VERSION ""

NS_ :

BS_:

BU_: REF_ECU AUT

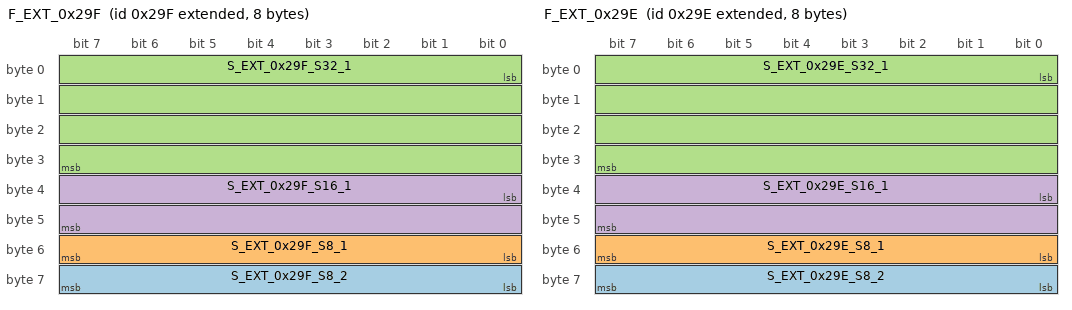
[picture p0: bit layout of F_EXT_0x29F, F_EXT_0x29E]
BO_ 2147484319 F_EXT_0x29F: 8 REF_ECU
 SG_ S_EXT_0x29F_S8_2 : 56|8@1- (1,0) [0|0] "" Vector__XXX
 SG_ S_EXT_0x29F_S8_1 : 48|8@1- (1,0) [0|0] "" Vector__XXX
 SG_ S_EXT_0x29F_S32_1 : 0|32@1- (1,0) [0|0] "" Vector__XXX
 SG_ S_EXT_0x29F_S16_1 : 32|16@1- (1,0) [0|0] "" Vector__XXX

BO_ 2147484318 F_EXT_0x29E: 8 REF_ECU
 SG_ S_EXT_0x29E_S8_2 : 56|8@1- (1,0) [0|0] "" Vector__XXX
 SG_ S_EXT_0x29E_S8_1 : 48|8@1- (1,0) [0|0] "" Vector__XXX
 SG_ S_EXT_0x29E_S32_1 : 0|32@1- (1,0) [0|0] "" Vector__XXX
 SG_ S_EXT_0x29E_S16_1 : 32|16@1- (1,0) [0|0] "" Vector__XXX

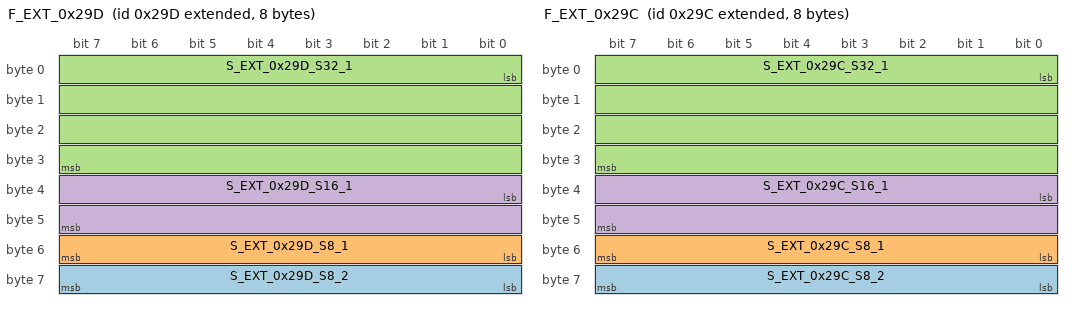
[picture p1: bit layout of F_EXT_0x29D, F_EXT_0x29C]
BO_ 2147484317 F_EXT_0x29D: 8 REF_ECU
 SG_ S_EXT_0x29D_S8_2 : 56|8@1- (1,0) [0|0] "" Vector__XXX
 SG_ S_EXT_0x29D_S8_1 : 48|8@1- (1,0) [0|0] "" Vector__XXX
 SG_ S_EXT_0x29D_S32_1 : 0|32@1- (1,0) [0|0] "" Vector__XXX
 SG_ S_EXT_0x29D_S16_1 : 32|16@1- (1,0) [0|0] "" Vector__XXX

BO_ 2147484316 F_EXT_0x29C: 8 REF_ECU
 SG_ S_EXT_0x29C_S8_2 : 56|8@1- (1,0) [0|0] "" Vector__XXX
 SG_ S_EXT_0x29C_S8_1 : 48|8@1- (1,0) [0|0] "" Vector__XXX
 SG_ S_EXT_0x29C_S32_1 : 0|32@1- (1,0) [0|0] "" Vector__XXX
 SG_ S_EXT_0x29C_S16_1 : 32|16@1- (1,0) [0|0] "" Vector__XXX

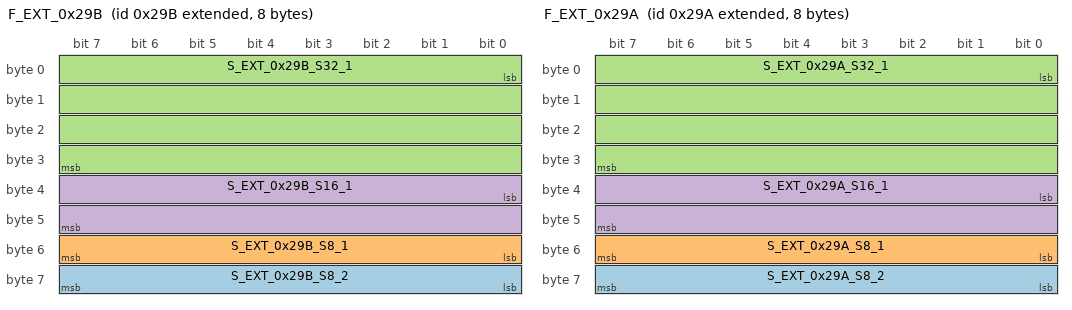
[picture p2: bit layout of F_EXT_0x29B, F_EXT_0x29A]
BO_ 2147484315 F_EXT_0x29B: 8 REF_ECU
 SG_ S_EXT_0x29B_S8_2 : 56|8@1- (1,0) [0|0] "" Vector__XXX
 SG_ S_EXT_0x29B_S8_1 : 48|8@1- (1,0) [0|0] "" Vector__XXX
 SG_ S_EXT_0x29B_S32_1 : 0|32@1- (1,0) [0|0] "" Vector__XXX
 SG_ S_EXT_0x29B_S16_1 : 32|16@1- (1,0) [0|0] "" Vector__XXX

BO_ 2147484314 F_EXT_0x29A: 8 REF_ECU
 SG_ S_EXT_0x29A_S8_2 : 56|8@1- (1,0) [0|0] "" Vector__XXX
 SG_ S_EXT_0x29A_S8_1 : 48|8@1- (1,0) [0|0] "" Vector__XXX
 SG_ S_EXT_0x29A_S32_1 : 0|32@1- (1,0) [0|0] "" Vector__XXX
 SG_ S_EXT_0x29A_S16_1 : 32|16@1- (1,0) [0|0] "" Vector__XXX

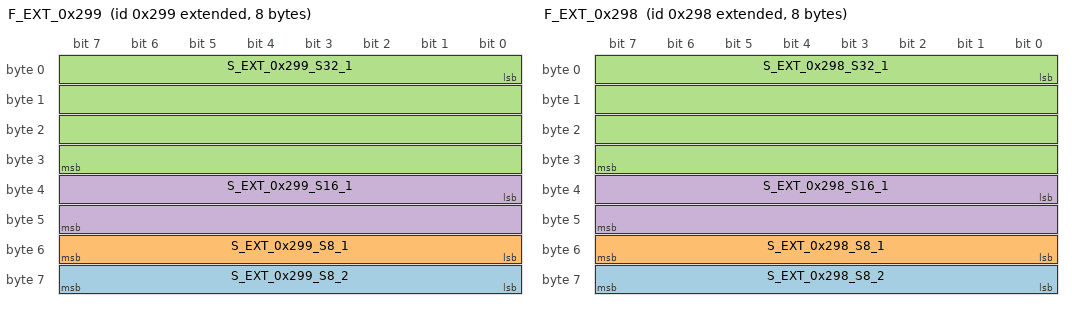
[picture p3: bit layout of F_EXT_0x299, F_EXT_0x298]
BO_ 2147484313 F_EXT_0x299: 8 REF_ECU
 SG_ S_EXT_0x299_S8_2 : 56|8@1- (1,0) [0|0] "" Vector__XXX
 SG_ S_EXT_0x299_S8_1 : 48|8@1- (1,0) [0|0] "" Vector__XXX
 SG_ S_EXT_0x299_S32_1 : 0|32@1- (1,0) [0|0] "" Vector__XXX
 SG_ S_EXT_0x299_S16_1 : 32|16@1- (1,0) [0|0] "" Vector__XXX

BO_ 2147484312 F_EXT_0x298: 8 REF_ECU
 SG_ S_EXT_0x298_S8_2 : 56|8@1- (1,0) [0|0] "" Vector__XXX
 SG_ S_EXT_0x298_S8_1 : 48|8@1- (1,0) [0|0] "" Vector__XXX
 SG_ S_EXT_0x298_S32_1 : 0|32@1- (1,0) [0|0] "" Vector__XXX
 SG_ S_EXT_0x298_S16_1 : 32|16@1- (1,0) [0|0] "" Vector__XXX

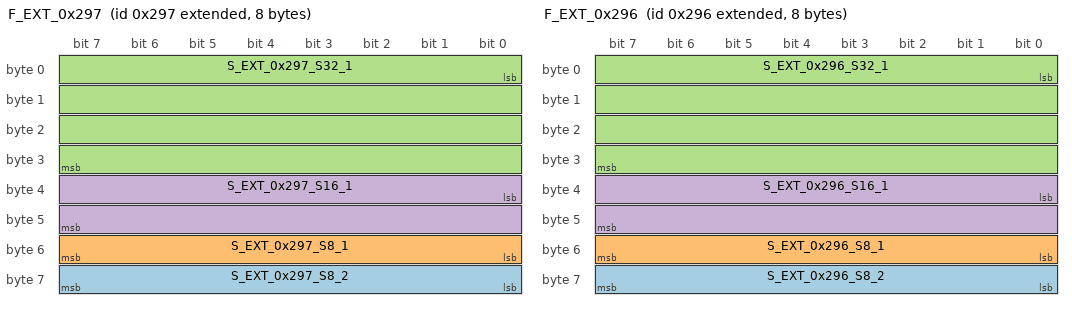
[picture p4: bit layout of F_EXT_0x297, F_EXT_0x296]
BO_ 2147484311 F_EXT_0x297: 8 REF_ECU
 SG_ S_EXT_0x297_S8_2 : 56|8@1- (1,0) [0|0] "" Vector__XXX
 SG_ S_EXT_0x297_S8_1 : 48|8@1- (1,0) [0|0] "" Vector__XXX
 SG_ S_EXT_0x297_S32_1 : 0|32@1- (1,0) [0|0] "" Vector__XXX
 SG_ S_EXT_0x297_S16_1 : 32|16@1- (1,0) [0|0] "" Vector__XXX

BO_ 2147484310 F_EXT_0x296: 8 REF_ECU
 SG_ S_EXT_0x296_S8_2 : 56|8@1- (1,0) [0|0] "" Vector__XXX
 SG_ S_EXT_0x296_S8_1 : 48|8@1- (1,0) [0|0] "" Vector__XXX
 SG_ S_EXT_0x296_S32_1 : 0|32@1- (1,0) [0|0] "" Vector__XXX
 SG_ S_EXT_0x296_S16_1 : 32|16@1- (1,0) [0|0] "" Vector__XXX

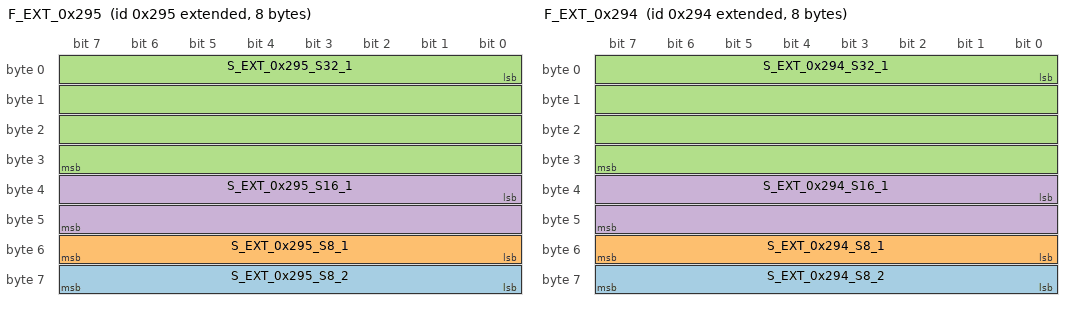
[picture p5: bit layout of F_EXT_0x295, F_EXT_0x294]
BO_ 2147484309 F_EXT_0x295: 8 REF_ECU
 SG_ S_EXT_0x295_S8_2 : 56|8@1- (1,0) [0|0] "" Vector__XXX
 SG_ S_EXT_0x295_S8_1 : 48|8@1- (1,0) [0|0] "" Vector__XXX
 SG_ S_EXT_0x295_S32_1 : 0|32@1- (1,0) [0|0] "" Vector__XXX
 SG_ S_EXT_0x295_S16_1 : 32|16@1- (1,0) [0|0] "" Vector__XXX

BO_ 2147484308 F_EXT_0x294: 8 REF_ECU
 SG_ S_EXT_0x294_S8_2 : 56|8@1- (1,0) [0|0] "" Vector__XXX
 SG_ S_EXT_0x294_S8_1 : 48|8@1- (1,0) [0|0] "" Vector__XXX
 SG_ S_EXT_0x294_S32_1 : 0|32@1- (1,0) [0|0] "" Vector__XXX
 SG_ S_EXT_0x294_S16_1 : 32|16@1- (1,0) [0|0] "" Vector__XXX

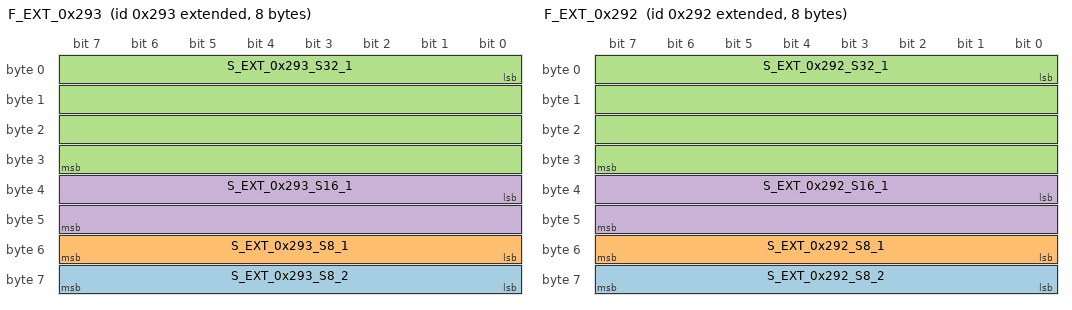
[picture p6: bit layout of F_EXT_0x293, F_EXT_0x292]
BO_ 2147484307 F_EXT_0x293: 8 REF_ECU
 SG_ S_EXT_0x293_S8_2 : 56|8@1- (1,0) [0|0] "" Vector__XXX
 SG_ S_EXT_0x293_S8_1 : 48|8@1- (1,0) [0|0] "" Vector__XXX
 SG_ S_EXT_0x293_S32_1 : 0|32@1- (1,0) [0|0] "" Vector__XXX
 SG_ S_EXT_0x293_S16_1 : 32|16@1- (1,0) [0|0] "" Vector__XXX

BO_ 2147484306 F_EXT_0x292: 8 REF_ECU
 SG_ S_EXT_0x292_S8_2 : 56|8@1- (1,0) [0|0] "" Vector__XXX
 SG_ S_EXT_0x292_S8_1 : 48|8@1- (1,0) [0|0] "" Vector__XXX
 SG_ S_EXT_0x292_S32_1 : 0|32@1- (1,0) [0|0] "" Vector__XXX
 SG_ S_EXT_0x292_S16_1 : 32|16@1- (1,0) [0|0] "" Vector__XXX

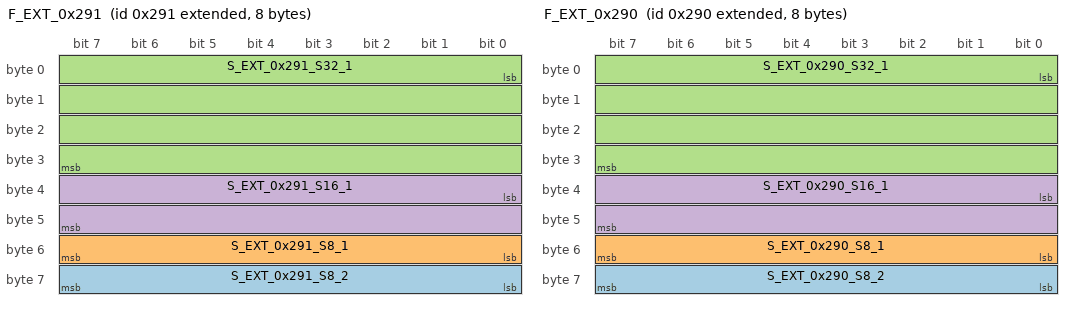
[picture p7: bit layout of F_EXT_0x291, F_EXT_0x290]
BO_ 2147484305 F_EXT_0x291: 8 REF_ECU
 SG_ S_EXT_0x291_S8_2 : 56|8@1- (1,0) [0|0] "" Vector__XXX
 SG_ S_EXT_0x291_S8_1 : 48|8@1- (1,0) [0|0] "" Vector__XXX
 SG_ S_EXT_0x291_S32_1 : 0|32@1- (1,0) [0|0] "" Vector__XXX
 SG_ S_EXT_0x291_S16_1 : 32|16@1- (1,0) [0|0] "" Vector__XXX

BO_ 2147484304 F_EXT_0x290: 8 REF_ECU
 SG_ S_EXT_0x290_S8_2 : 56|8@1- (1,0) [0|0] "" Vector__XXX
 SG_ S_EXT_0x290_S8_1 : 48|8@1- (1,0) [0|0] "" Vector__XXX
 SG_ S_EXT_0x290_S32_1 : 0|32@1- (1,0) [0|0] "" Vector__XXX
 SG_ S_EXT_0x290_S16_1 : 32|16@1- (1,0) [0|0] "" Vector__XXX

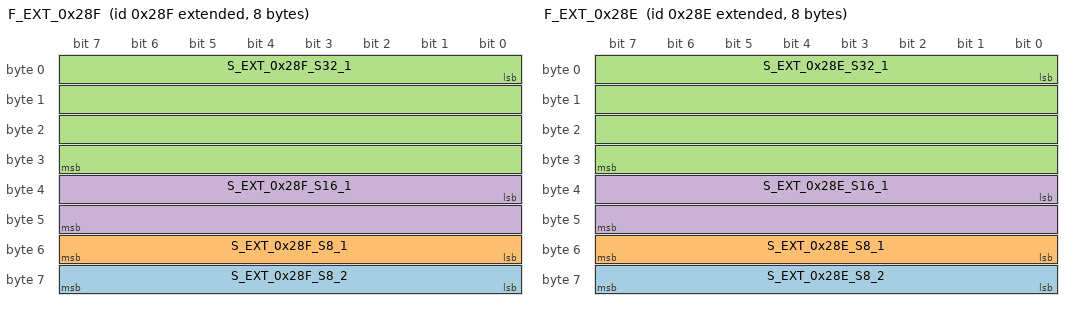
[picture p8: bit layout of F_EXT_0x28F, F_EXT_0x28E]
BO_ 2147484303 F_EXT_0x28F: 8 REF_ECU
 SG_ S_EXT_0x28F_S8_2 : 56|8@1- (1,0) [0|0] "" Vector__XXX
 SG_ S_EXT_0x28F_S8_1 : 48|8@1- (1,0) [0|0] "" Vector__XXX
 SG_ S_EXT_0x28F_S32_1 : 0|32@1- (1,0) [0|0] "" Vector__XXX
 SG_ S_EXT_0x28F_S16_1 : 32|16@1- (1,0) [0|0] "" Vector__XXX

BO_ 2147484302 F_EXT_0x28E: 8 REF_ECU
 SG_ S_EXT_0x28E_S8_2 : 56|8@1- (1,0) [0|0] "" Vector__XXX
 SG_ S_EXT_0x28E_S8_1 : 48|8@1- (1,0) [0|0] "" Vector__XXX
 SG_ S_EXT_0x28E_S32_1 : 0|32@1- (1,0) [0|0] "" Vector__XXX
 SG_ S_EXT_0x28E_S16_1 : 32|16@1- (1,0) [0|0] "" Vector__XXX

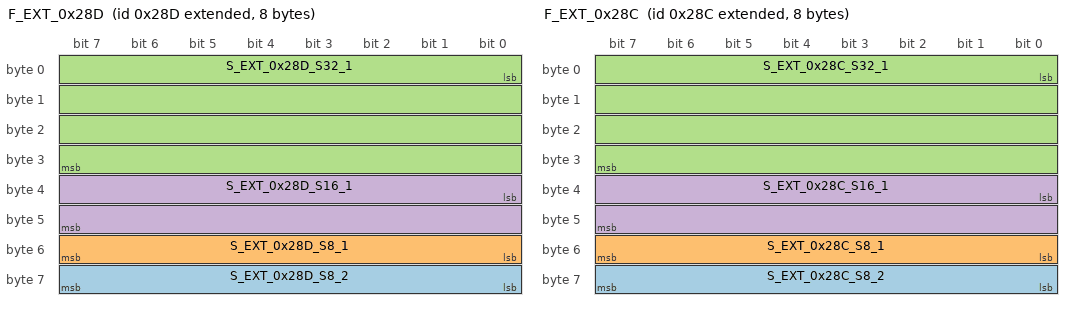
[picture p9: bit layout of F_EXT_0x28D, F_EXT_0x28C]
BO_ 2147484301 F_EXT_0x28D: 8 REF_ECU
 SG_ S_EXT_0x28D_S8_2 : 56|8@1- (1,0) [0|0] "" Vector__XXX
 SG_ S_EXT_0x28D_S8_1 : 48|8@1- (1,0) [0|0] "" Vector__XXX
 SG_ S_EXT_0x28D_S32_1 : 0|32@1- (1,0) [0|0] "" Vector__XXX
 SG_ S_EXT_0x28D_S16_1 : 32|16@1- (1,0) [0|0] "" Vector__XXX

BO_ 2147484300 F_EXT_0x28C: 8 REF_ECU
 SG_ S_EXT_0x28C_S8_2 : 56|8@1- (1,0) [0|0] "" Vector__XXX
 SG_ S_EXT_0x28C_S8_1 : 48|8@1- (1,0) [0|0] "" Vector__XXX
 SG_ S_EXT_0x28C_S32_1 : 0|32@1- (1,0) [0|0] "" Vector__XXX
 SG_ S_EXT_0x28C_S16_1 : 32|16@1- (1,0) [0|0] "" Vector__XXX

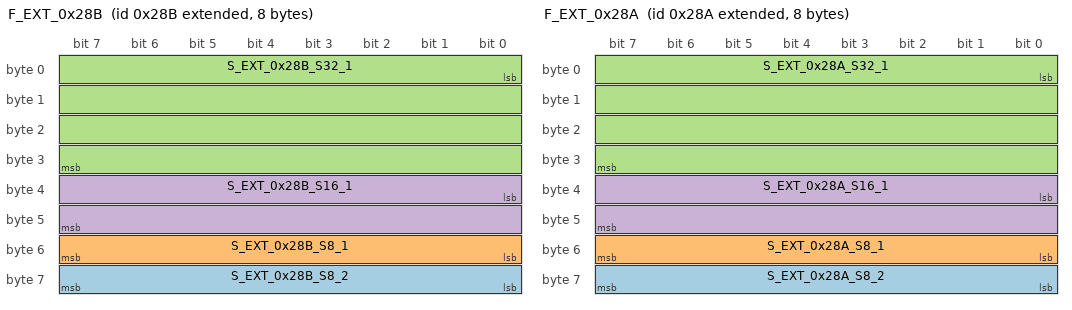
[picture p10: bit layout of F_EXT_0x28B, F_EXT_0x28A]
BO_ 2147484299 F_EXT_0x28B: 8 REF_ECU
 SG_ S_EXT_0x28B_S8_2 : 56|8@1- (1,0) [0|0] "" Vector__XXX
 SG_ S_EXT_0x28B_S8_1 : 48|8@1- (1,0) [0|0] "" Vector__XXX
 SG_ S_EXT_0x28B_S32_1 : 0|32@1- (1,0) [0|0] "" Vector__XXX
 SG_ S_EXT_0x28B_S16_1 : 32|16@1- (1,0) [0|0] "" Vector__XXX

BO_ 2147484298 F_EXT_0x28A: 8 REF_ECU
 SG_ S_EXT_0x28A_S8_2 : 56|8@1- (1,0) [0|0] "" Vector__XXX
 SG_ S_EXT_0x28A_S8_1 : 48|8@1- (1,0) [0|0] "" Vector__XXX
 SG_ S_EXT_0x28A_S32_1 : 0|32@1- (1,0) [0|0] "" Vector__XXX
 SG_ S_EXT_0x28A_S16_1 : 32|16@1- (1,0) [0|0] "" Vector__XXX

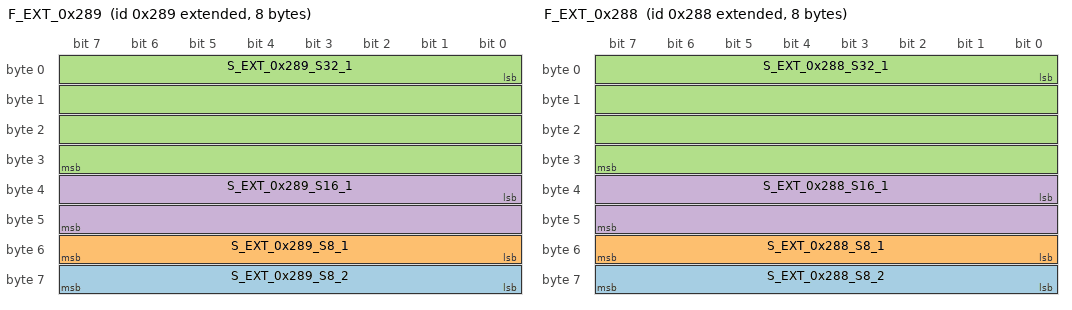
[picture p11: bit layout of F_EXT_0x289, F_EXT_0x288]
BO_ 2147484297 F_EXT_0x289: 8 REF_ECU
 SG_ S_EXT_0x289_S8_2 : 56|8@1- (1,0) [0|0] "" Vector__XXX
 SG_ S_EXT_0x289_S8_1 : 48|8@1- (1,0) [0|0] "" Vector__XXX
 SG_ S_EXT_0x289_S32_1 : 0|32@1- (1,0) [0|0] "" Vector__XXX
 SG_ S_EXT_0x289_S16_1 : 32|16@1- (1,0) [0|0] "" Vector__XXX

BO_ 2147484296 F_EXT_0x288: 8 REF_ECU
 SG_ S_EXT_0x288_S8_2 : 56|8@1- (1,0) [0|0] "" Vector__XXX
 SG_ S_EXT_0x288_S8_1 : 48|8@1- (1,0) [0|0] "" Vector__XXX
 SG_ S_EXT_0x288_S32_1 : 0|32@1- (1,0) [0|0] "" Vector__XXX
 SG_ S_EXT_0x288_S16_1 : 32|16@1- (1,0) [0|0] "" Vector__XXX

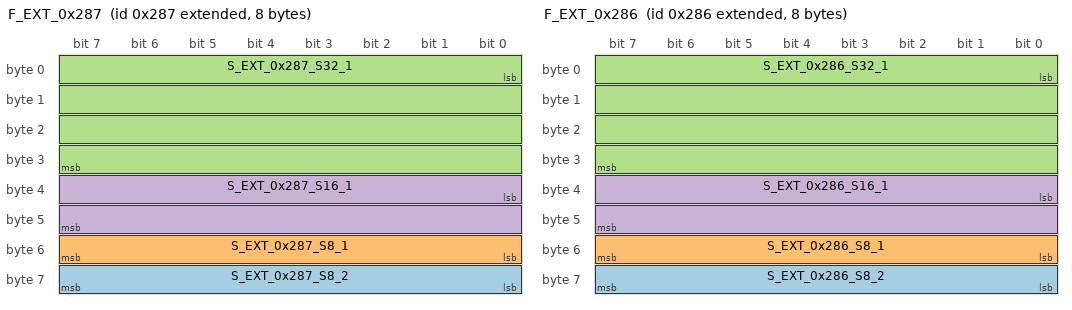
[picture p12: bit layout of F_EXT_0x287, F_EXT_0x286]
BO_ 2147484295 F_EXT_0x287: 8 REF_ECU
 SG_ S_EXT_0x287_S8_2 : 56|8@1- (1,0) [0|0] "" Vector__XXX
 SG_ S_EXT_0x287_S8_1 : 48|8@1- (1,0) [0|0] "" Vector__XXX
 SG_ S_EXT_0x287_S32_1 : 0|32@1- (1,0) [0|0] "" Vector__XXX
 SG_ S_EXT_0x287_S16_1 : 32|16@1- (1,0) [0|0] "" Vector__XXX

BO_ 2147484294 F_EXT_0x286: 8 REF_ECU
 SG_ S_EXT_0x286_S8_2 : 56|8@1- (1,0) [0|0] "" Vector__XXX
 SG_ S_EXT_0x286_S8_1 : 48|8@1- (1,0) [0|0] "" Vector__XXX
 SG_ S_EXT_0x286_S32_1 : 0|32@1- (1,0) [0|0] "" Vector__XXX
 SG_ S_EXT_0x286_S16_1 : 32|16@1- (1,0) [0|0] "" Vector__XXX

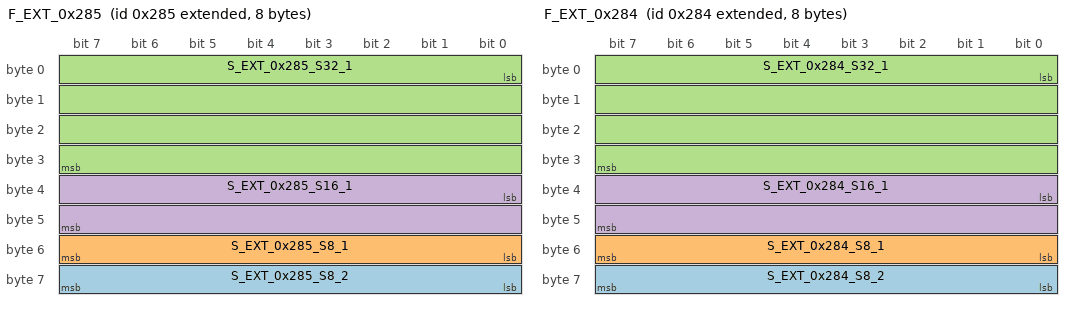
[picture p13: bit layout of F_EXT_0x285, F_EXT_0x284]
BO_ 2147484293 F_EXT_0x285: 8 REF_ECU
 SG_ S_EXT_0x285_S8_2 : 56|8@1- (1,0) [0|0] "" Vector__XXX
 SG_ S_EXT_0x285_S8_1 : 48|8@1- (1,0) [0|0] "" Vector__XXX
 SG_ S_EXT_0x285_S32_1 : 0|32@1- (1,0) [0|0] "" Vector__XXX
 SG_ S_EXT_0x285_S16_1 : 32|16@1- (1,0) [0|0] "" Vector__XXX

BO_ 2147484292 F_EXT_0x284: 8 REF_ECU
 SG_ S_EXT_0x284_S8_2 : 56|8@1- (1,0) [0|0] "" Vector__XXX
 SG_ S_EXT_0x284_S8_1 : 48|8@1- (1,0) [0|0] "" Vector__XXX
 SG_ S_EXT_0x284_S32_1 : 0|32@1- (1,0) [0|0] "" Vector__XXX
 SG_ S_EXT_0x284_S16_1 : 32|16@1- (1,0) [0|0] "" Vector__XXX

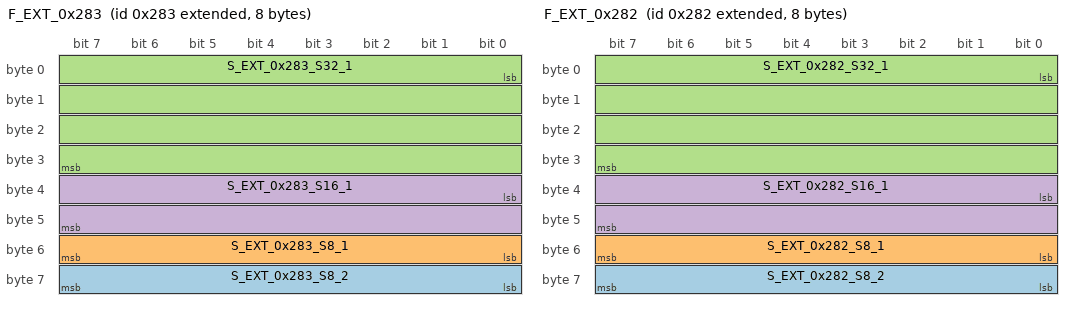
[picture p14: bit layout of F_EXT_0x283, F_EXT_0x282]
BO_ 2147484291 F_EXT_0x283: 8 REF_ECU
 SG_ S_EXT_0x283_S8_2 : 56|8@1- (1,0) [0|0] "" Vector__XXX
 SG_ S_EXT_0x283_S8_1 : 48|8@1- (1,0) [0|0] "" Vector__XXX
 SG_ S_EXT_0x283_S32_1 : 0|32@1- (1,0) [0|0] "" Vector__XXX
 SG_ S_EXT_0x283_S16_1 : 32|16@1- (1,0) [0|0] "" Vector__XXX

BO_ 2147484290 F_EXT_0x282: 8 REF_ECU
 SG_ S_EXT_0x282_S8_2 : 56|8@1- (1,0) [0|0] "" Vector__XXX
 SG_ S_EXT_0x282_S8_1 : 48|8@1- (1,0) [0|0] "" Vector__XXX
 SG_ S_EXT_0x282_S32_1 : 0|32@1- (1,0) [0|0] "" Vector__XXX
 SG_ S_EXT_0x282_S16_1 : 32|16@1- (1,0) [0|0] "" Vector__XXX

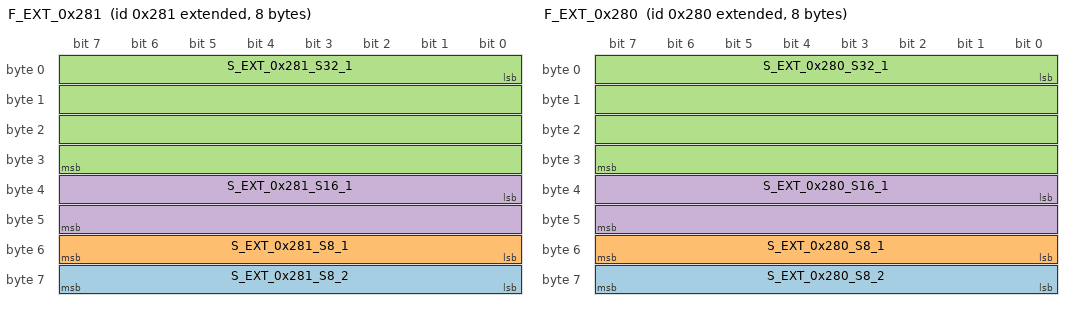
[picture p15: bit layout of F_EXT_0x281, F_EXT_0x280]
BO_ 2147484289 F_EXT_0x281: 8 REF_ECU
 SG_ S_EXT_0x281_S8_2 : 56|8@1- (1,0) [0|0] "" Vector__XXX
 SG_ S_EXT_0x281_S8_1 : 48|8@1- (1,0) [0|0] "" Vector__XXX
 SG_ S_EXT_0x281_S32_1 : 0|32@1- (1,0) [0|0] "" Vector__XXX
 SG_ S_EXT_0x281_S16_1 : 32|16@1- (1,0) [0|0] "" Vector__XXX

BO_ 2147484288 F_EXT_0x280: 8 REF_ECU
 SG_ S_EXT_0x280_S8_2 : 56|8@1- (1,0) [0|0] "" Vector__XXX
 SG_ S_EXT_0x280_S8_1 : 48|8@1- (1,0) [0|0] "" Vector__XXX
 SG_ S_EXT_0x280_S32_1 : 0|32@1- (1,0) [0|0] "" Vector__XXX
 SG_ S_EXT_0x280_S16_1 : 32|16@1- (1,0) [0|0] "" Vector__XXX

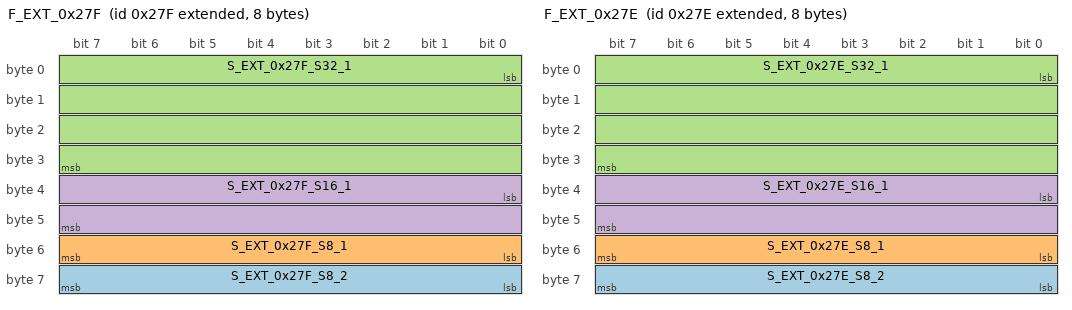
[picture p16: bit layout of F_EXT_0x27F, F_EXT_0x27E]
BO_ 2147484287 F_EXT_0x27F: 8 REF_ECU
 SG_ S_EXT_0x27F_S8_2 : 56|8@1- (1,0) [0|0] "" Vector__XXX
 SG_ S_EXT_0x27F_S8_1 : 48|8@1- (1,0) [0|0] "" Vector__XXX
 SG_ S_EXT_0x27F_S32_1 : 0|32@1- (1,0) [0|0] "" Vector__XXX
 SG_ S_EXT_0x27F_S16_1 : 32|16@1- (1,0) [0|0] "" Vector__XXX

BO_ 2147484286 F_EXT_0x27E: 8 REF_ECU
 SG_ S_EXT_0x27E_S8_2 : 56|8@1- (1,0) [0|0] "" Vector__XXX
 SG_ S_EXT_0x27E_S8_1 : 48|8@1- (1,0) [0|0] "" Vector__XXX
 SG_ S_EXT_0x27E_S32_1 : 0|32@1- (1,0) [0|0] "" Vector__XXX
 SG_ S_EXT_0x27E_S16_1 : 32|16@1- (1,0) [0|0] "" Vector__XXX

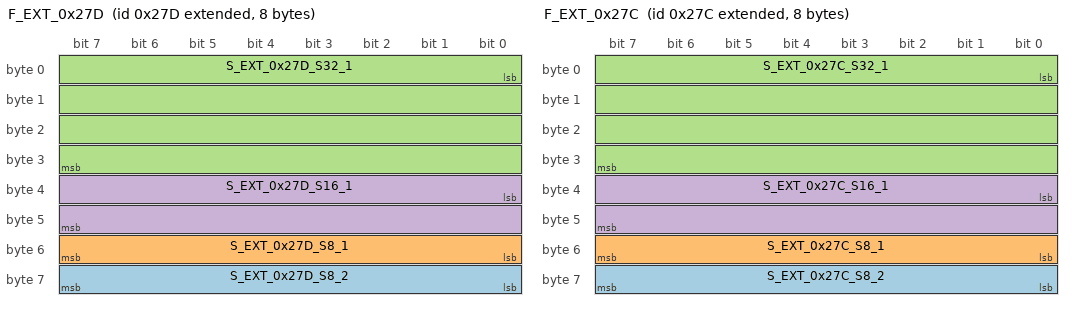
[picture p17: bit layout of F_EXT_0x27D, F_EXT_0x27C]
BO_ 2147484285 F_EXT_0x27D: 8 REF_ECU
 SG_ S_EXT_0x27D_S8_2 : 56|8@1- (1,0) [0|0] "" Vector__XXX
 SG_ S_EXT_0x27D_S8_1 : 48|8@1- (1,0) [0|0] "" Vector__XXX
 SG_ S_EXT_0x27D_S32_1 : 0|32@1- (1,0) [0|0] "" Vector__XXX
 SG_ S_EXT_0x27D_S16_1 : 32|16@1- (1,0) [0|0] "" Vector__XXX

BO_ 2147484284 F_EXT_0x27C: 8 REF_ECU
 SG_ S_EXT_0x27C_S8_2 : 56|8@1- (1,0) [0|0] "" Vector__XXX
 SG_ S_EXT_0x27C_S8_1 : 48|8@1- (1,0) [0|0] "" Vector__XXX
 SG_ S_EXT_0x27C_S32_1 : 0|32@1- (1,0) [0|0] "" Vector__XXX
 SG_ S_EXT_0x27C_S16_1 : 32|16@1- (1,0) [0|0] "" Vector__XXX

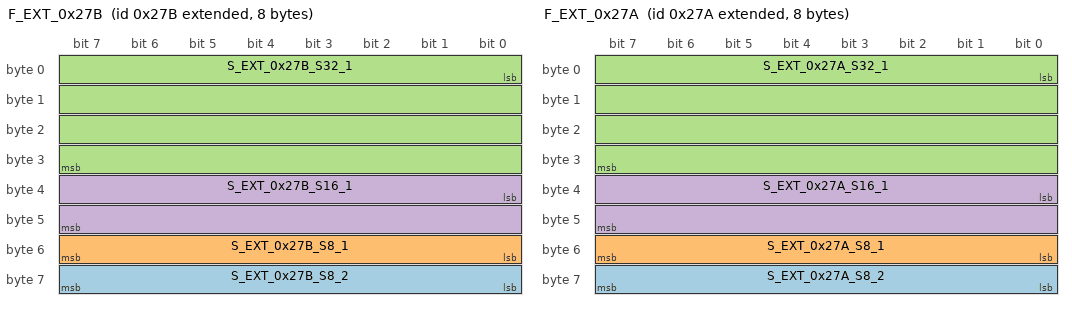
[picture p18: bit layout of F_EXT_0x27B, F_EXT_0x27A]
BO_ 2147484283 F_EXT_0x27B: 8 REF_ECU
 SG_ S_EXT_0x27B_S8_2 : 56|8@1- (1,0) [0|0] "" Vector__XXX
 SG_ S_EXT_0x27B_S8_1 : 48|8@1- (1,0) [0|0] "" Vector__XXX
 SG_ S_EXT_0x27B_S32_1 : 0|32@1- (1,0) [0|0] "" Vector__XXX
 SG_ S_EXT_0x27B_S16_1 : 32|16@1- (1,0) [0|0] "" Vector__XXX

BO_ 2147484282 F_EXT_0x27A: 8 REF_ECU
 SG_ S_EXT_0x27A_S8_2 : 56|8@1- (1,0) [0|0] "" Vector__XXX
 SG_ S_EXT_0x27A_S8_1 : 48|8@1- (1,0) [0|0] "" Vector__XXX
 SG_ S_EXT_0x27A_S32_1 : 0|32@1- (1,0) [0|0] "" Vector__XXX
 SG_ S_EXT_0x27A_S16_1 : 32|16@1- (1,0) [0|0] "" Vector__XXX

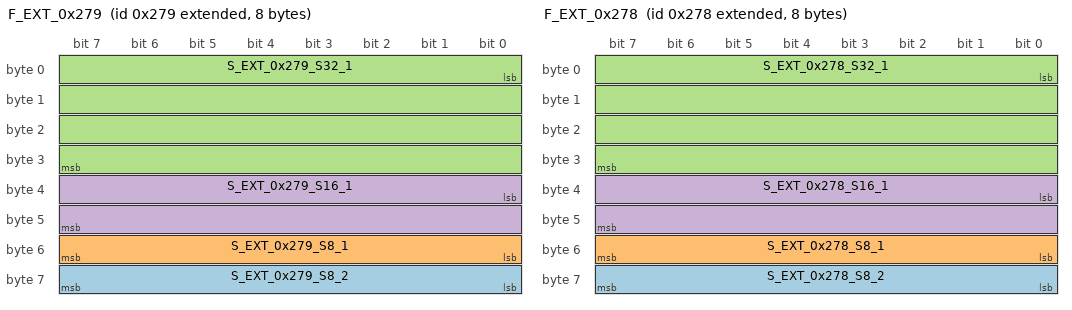
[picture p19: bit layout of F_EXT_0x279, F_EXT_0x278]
BO_ 2147484281 F_EXT_0x279: 8 REF_ECU
 SG_ S_EXT_0x279_S8_2 : 56|8@1- (1,0) [0|0] "" Vector__XXX
 SG_ S_EXT_0x279_S8_1 : 48|8@1- (1,0) [0|0] "" Vector__XXX
 SG_ S_EXT_0x279_S32_1 : 0|32@1- (1,0) [0|0] "" Vector__XXX
 SG_ S_EXT_0x279_S16_1 : 32|16@1- (1,0) [0|0] "" Vector__XXX

BO_ 2147484280 F_EXT_0x278: 8 REF_ECU
 SG_ S_EXT_0x278_S8_2 : 56|8@1- (1,0) [0|0] "" Vector__XXX
 SG_ S_EXT_0x278_S8_1 : 48|8@1- (1,0) [0|0] "" Vector__XXX
 SG_ S_EXT_0x278_S32_1 : 0|32@1- (1,0) [0|0] "" Vector__XXX
 SG_ S_EXT_0x278_S16_1 : 32|16@1- (1,0) [0|0] "" Vector__XXX

BO_ 2147484279 F_EXT_0x277: 8 REF_ECU
 SG_ S_EXT_0x277_S8_2 : 56|8@1- (1,0) [0|0] "" Vector__XXX
 SG_ S_EXT_0x277_S8_1 : 48|8@1- (1,0) [0|0] "" Vector__XXX
 SG_ S_EXT_0x277_S32_1 : 0|32@1- (1,0) [0|0] "" Vector__XXX
 SG_ S_EXT_0x277_S16_1 : 32|16@1- (1,0) [0|0] "" Vector__XXX

BO_ 2147484278 F_EXT_0x276: 8 REF_ECU
 SG_ S_EXT_0x276_S8_2 : 56|8@1- (1,0) [0|0] "" Vector__XXX
 SG_ S_EXT_0x276_S8_1 : 48|8@1- (1,0) [0|0] "" Vector__XXX
 SG_ S_EXT_0x276_S32_1 : 0|32@1- (1,0) [0|0] "" Vector__XXX
 SG_ S_EXT_0x276_S16_1 : 32|16@1- (1,0) [0|0] "" Vector__XXX

BO_ 2147484277 F_EXT_0x275: 8 REF_ECU
 SG_ S_EXT_0x275_S8_2 : 56|8@1- (1,0) [0|0] "" Vector__XXX
 SG_ S_EXT_0x275_S8_1 : 48|8@1- (1,0) [0|0] "" Vector__XXX
 SG_ S_EXT_0x275_S32_1 : 0|32@1- (1,0) [0|0] "" Vector__XXX
 SG_ S_EXT_0x275_S16_1 : 32|16@1- (1,0) [0|0] "" Vector__XXX

BO_ 2147484276 F_EXT_0x274: 8 REF_ECU
 SG_ S_EXT_0x274_S8_2 : 56|8@1- (1,0) [0|0] "" Vector__XXX
 SG_ S_EXT_0x274_S8_1 : 48|8@1- (1,0) [0|0] "" Vector__XXX
 SG_ S_EXT_0x274_S32_1 : 0|32@1- (1,0) [0|0] "" Vector__XXX
 SG_ S_EXT_0x274_S16_1 : 32|16@1- (1,0) [0|0] "" Vector__XXX

BO_ 2147484275 F_EXT_0x273: 8 REF_ECU
 SG_ S_EXT_0x273_S8_2 : 56|8@1- (1,0) [0|0] "" Vector__XXX
 SG_ S_EXT_0x273_S8_1 : 48|8@1- (1,0) [0|0] "" Vector__XXX
 SG_ S_EXT_0x273_S32_1 : 0|32@1- (1,0) [0|0] "" Vector__XXX
 SG_ S_EXT_0x273_S16_1 : 32|16@1- (1,0) [0|0] "" Vector__XXX

BO_ 2147484274 F_EXT_0x272: 8 REF_ECU
 SG_ S_EXT_0x272_S8_2 : 56|8@1- (1,0) [0|0] "" Vector__XXX
 SG_ S_EXT_0x272_S8_1 : 48|8@1- (1,0) [0|0] "" Vector__XXX
 SG_ S_EXT_0x272_S32_1 : 0|32@1- (1,0) [0|0] "" Vector__XXX
 SG_ S_EXT_0x272_S16_1 : 32|16@1- (1,0) [0|0] "" Vector__XXX

BO_ 2147484273 F_EXT_0x271: 8 REF_ECU
 SG_ S_EXT_0x271_S8_2 : 56|8@1- (1,0) [0|0] "" Vector__XXX
 SG_ S_EXT_0x271_S8_1 : 48|8@1- (1,0) [0|0] "" Vector__XXX
 SG_ S_EXT_0x271_S32_1 : 0|32@1- (1,0) [0|0] "" Vector__XXX
 SG_ S_EXT_0x271_S16_1 : 32|16@1- (1,0) [0|0] "" Vector__XXX

BO_ 2147484272 F_EXT_0x270: 8 REF_ECU
 SG_ S_EXT_0x270_S8_2 : 56|8@1- (1,0) [0|0] "" Vector__XXX
 SG_ S_EXT_0x270_S8_1 : 48|8@1- (1,0) [0|0] "" Vector__XXX
 SG_ S_EXT_0x270_S32_1 : 0|32@1- (1,0) [0|0] "" Vector__XXX
 SG_ S_EXT_0x270_S16_1 : 32|16@1- (1,0) [0|0] "" Vector__XXX

BO_ 2147484271 F_EXT_0x26F: 8 REF_ECU
 SG_ S_EXT_0x26F_S8_2 : 56|8@1- (1,0) [0|0] "" Vector__XXX
 SG_ S_EXT_0x26F_S8_1 : 48|8@1- (1,0) [0|0] "" Vector__XXX
 SG_ S_EXT_0x26F_S32_1 : 0|32@1- (1,0) [0|0] "" Vector__XXX
 SG_ S_EXT_0x26F_S16_1 : 32|16@1- (1,0) [0|0] "" Vector__XXX

BO_ 2147484270 F_EXT_0x26E: 8 REF_ECU
 SG_ S_EXT_0x26E_S8_2 : 56|8@1- (1,0) [0|0] "" Vector__XXX
 SG_ S_EXT_0x26E_S8_1 : 48|8@1- (1,0) [0|0] "" Vector__XXX
 SG_ S_EXT_0x26E_S32_1 : 0|32@1- (1,0) [0|0] "" Vector__XXX
 SG_ S_EXT_0x26E_S16_1 : 32|16@1- (1,0) [0|0] "" Vector__XXX

BO_ 2147484269 F_EXT_0x26D: 8 REF_ECU
 SG_ S_EXT_0x26D_S8_2 : 56|8@1- (1,0) [0|0] "" Vector__XXX
 SG_ S_EXT_0x26D_S8_1 : 48|8@1- (1,0) [0|0] "" Vector__XXX
 SG_ S_EXT_0x26D_S32_1 : 0|32@1- (1,0) [0|0] "" Vector__XXX
 SG_ S_EXT_0x26D_S16_1 : 32|16@1- (1,0) [0|0] "" Vector__XXX

BO_ 2147484268 F_EXT_0x26C: 8 REF_ECU
 SG_ S_EXT_0x26C_S8_2 : 56|8@1- (1,0) [0|0] "" Vector__XXX
 SG_ S_EXT_0x26C_S8_1 : 48|8@1- (1,0) [0|0] "" Vector__XXX
 SG_ S_EXT_0x26C_S32_1 : 0|32@1- (1,0) [0|0] "" Vector__XXX
 SG_ S_EXT_0x26C_S16_1 : 32|16@1- (1,0) [0|0] "" Vector__XXX

BO_ 2147484267 F_EXT_0x26B: 8 REF_ECU
 SG_ S_EXT_0x26B_S8_2 : 56|8@1- (1,0) [0|0] "" Vector__XXX
 SG_ S_EXT_0x26B_S8_1 : 48|8@1- (1,0) [0|0] "" Vector__XXX
 SG_ S_EXT_0x26B_S32_1 : 0|32@1- (1,0) [0|0] "" Vector__XXX
 SG_ S_EXT_0x26B_S16_1 : 32|16@1- (1,0) [0|0] "" Vector__XXX

BO_ 2147484266 F_EXT_0x26A: 8 REF_ECU
 SG_ S_EXT_0x26A_S8_2 : 56|8@1- (1,0) [0|0] "" Vector__XXX
 SG_ S_EXT_0x26A_S8_1 : 48|8@1- (1,0) [0|0] "" Vector__XXX
 SG_ S_EXT_0x26A_S32_1 : 0|32@1- (1,0) [0|0] "" Vector__XXX
 SG_ S_EXT_0x26A_S16_1 : 32|16@1- (1,0) [0|0] "" Vector__XXX

BO_ 2147484265 F_EXT_0x269: 8 REF_ECU
 SG_ S_EXT_0x269_S8_2 : 56|8@1- (1,0) [0|0] "" Vector__XXX
 SG_ S_EXT_0x269_S8_1 : 48|8@1- (1,0) [0|0] "" Vector__XXX
 SG_ S_EXT_0x269_S32_1 : 0|32@1- (1,0) [0|0] "" Vector__XXX
 SG_ S_EXT_0x269_S16_1 : 32|16@1- (1,0) [0|0] "" Vector__XXX

BO_ 2147484264 F_EXT_0x268: 8 REF_ECU
 SG_ S_EXT_0x268_S8_2 : 56|8@1- (1,0) [0|0] "" Vector__XXX
 SG_ S_EXT_0x268_S8_1 : 48|8@1- (1,0) [0|0] "" Vector__XXX
 SG_ S_EXT_0x268_S32_1 : 0|32@1- (1,0) [0|0] "" Vector__XXX
 SG_ S_EXT_0x268_S16_1 : 32|16@1- (1,0) [0|0] "" Vector__XXX

BO_ 2147484263 F_EXT_0x267: 8 REF_ECU
 SG_ S_EXT_0x267_S8_2 : 56|8@1- (1,0) [0|0] "" Vector__XXX
 SG_ S_EXT_0x267_S8_1 : 48|8@1- (1,0) [0|0] "" Vector__XXX
 SG_ S_EXT_0x267_S32_1 : 0|32@1- (1,0) [0|0] "" Vector__XXX
 SG_ S_EXT_0x267_S16_1 : 32|16@1- (1,0) [0|0] "" Vector__XXX

BO_ 2147484262 F_EXT_0x266: 8 REF_ECU
 SG_ S_EXT_0x266_S8_2 : 56|8@1- (1,0) [0|0] "" Vector__XXX
 SG_ S_EXT_0x266_S8_1 : 48|8@1- (1,0) [0|0] "" Vector__XXX
 SG_ S_EXT_0x266_S32_1 : 0|32@1- (1,0) [0|0] "" Vector__XXX
 SG_ S_EXT_0x266_S16_1 : 32|16@1- (1,0) [0|0] "" Vector__XXX

BO_ 2147484261 F_EXT_0x265: 8 REF_ECU
 SG_ S_EXT_0x265_S8_2 : 56|8@1- (1,0) [0|0] "" Vector__XXX
 SG_ S_EXT_0x265_S8_1 : 48|8@1- (1,0) [0|0] "" Vector__XXX
 SG_ S_EXT_0x265_S32_1 : 0|32@1- (1,0) [0|0] "" Vector__XXX
 SG_ S_EXT_0x265_S16_1 : 32|16@1- (1,0) [0|0] "" Vector__XXX

BO_ 2147484260 F_EXT_0x264: 8 REF_ECU
 SG_ S_EXT_0x264_S8_2 : 56|8@1- (1,0) [0|0] "" Vector__XXX
 SG_ S_EXT_0x264_S8_1 : 48|8@1- (1,0) [0|0] "" Vector__XXX
 SG_ S_EXT_0x264_S32_1 : 0|32@1- (1,0) [0|0] "" Vector__XXX
 SG_ S_EXT_0x264_S16_1 : 32|16@1- (1,0) [0|0] "" Vector__XXX

BO_ 2147484259 F_EXT_0x263: 8 REF_ECU
 SG_ S_EXT_0x263_S8_2 : 56|8@1- (1,0) [0|0] "" Vector__XXX
 SG_ S_EXT_0x263_S8_1 : 48|8@1- (1,0) [0|0] "" Vector__XXX
 SG_ S_EXT_0x263_S32_1 : 0|32@1- (1,0) [0|0] "" Vector__XXX
 SG_ S_EXT_0x263_S16_1 : 32|16@1- (1,0) [0|0] "" Vector__XXX

BO_ 2147484258 F_EXT_0x262: 8 REF_ECU
 SG_ S_EXT_0x262_S8_2 : 56|8@1- (1,0) [0|0] "" Vector__XXX
 SG_ S_EXT_0x262_S8_1 : 48|8@1- (1,0) [0|0] "" Vector__XXX
 SG_ S_EXT_0x262_S32_1 : 0|32@1- (1,0) [0|0] "" Vector__XXX
 SG_ S_EXT_0x262_S16_1 : 32|16@1- (1,0) [0|0] "" Vector__XXX

BO_ 2147484257 F_EXT_0x261: 8 REF_ECU
 SG_ S_EXT_0x261_S8_2 : 56|8@1- (1,0) [0|0] "" Vector__XXX
 SG_ S_EXT_0x261_S8_1 : 48|8@1- (1,0) [0|0] "" Vector__XXX
 SG_ S_EXT_0x261_S32_1 : 0|32@1- (1,0) [0|0] "" Vector__XXX
 SG_ S_EXT_0x261_S16_1 : 32|16@1- (1,0) [0|0] "" Vector__XXX

BO_ 2147484256 F_EXT_0x260: 8 REF_ECU
 SG_ S_EXT_0x260_S8_2 : 56|8@1- (1,0) [0|0] "" Vector__XXX
 SG_ S_EXT_0x260_S8_1 : 48|8@1- (1,0) [0|0] "" Vector__XXX
 SG_ S_EXT_0x260_S32_1 : 0|32@1- (1,0) [0|0] "" Vector__XXX
 SG_ S_EXT_0x260_S16_1 : 32|16@1- (1,0) [0|0] "" Vector__XXX

BO_ 2147484255 F_EXT_0x25F: 8 REF_ECU
 SG_ S_EXT_0x25F_S8_2 : 56|8@1- (1,0) [0|0] "" Vector__XXX
 SG_ S_EXT_0x25F_S8_1 : 48|8@1- (1,0) [0|0] "" Vector__XXX
 SG_ S_EXT_0x25F_S32_1 : 0|32@1- (1,0) [0|0] "" Vector__XXX
 SG_ S_EXT_0x25F_S16_1 : 32|16@1- (1,0) [0|0] "" Vector__XXX

BO_ 2147484254 F_EXT_0x25E: 8 REF_ECU
 SG_ S_EXT_0x25E_S8_2 : 56|8@1- (1,0) [0|0] "" Vector__XXX
 SG_ S_EXT_0x25E_S8_1 : 48|8@1- (1,0) [0|0] "" Vector__XXX
 SG_ S_EXT_0x25E_S32_1 : 0|32@1- (1,0) [0|0] "" Vector__XXX
 SG_ S_EXT_0x25E_S16_1 : 32|16@1- (1,0) [0|0] "" Vector__XXX

BO_ 2147484253 F_EXT_0x25D: 8 REF_ECU
 SG_ S_EXT_0x25D_S8_2 : 56|8@1- (1,0) [0|0] "" Vector__XXX
 SG_ S_EXT_0x25D_S8_1 : 48|8@1- (1,0) [0|0] "" Vector__XXX
 SG_ S_EXT_0x25D_S32_1 : 0|32@1- (1,0) [0|0] "" Vector__XXX
 SG_ S_EXT_0x25D_S16_1 : 32|16@1- (1,0) [0|0] "" Vector__XXX

BO_ 2147484252 F_EXT_0x25C: 8 REF_ECU
 SG_ S_EXT_0x25C_S8_2 : 56|8@1- (1,0) [0|0] "" Vector__XXX
 SG_ S_EXT_0x25C_S8_1 : 48|8@1- (1,0) [0|0] "" Vector__XXX
 SG_ S_EXT_0x25C_S32_1 : 0|32@1- (1,0) [0|0] "" Vector__XXX
 SG_ S_EXT_0x25C_S16_1 : 32|16@1- (1,0) [0|0] "" Vector__XXX

BO_ 2147484251 F_EXT_0x25B: 8 REF_ECU
 SG_ S_EXT_0x25B_S8_2 : 56|8@1- (1,0) [0|0] "" Vector__XXX
 SG_ S_EXT_0x25B_S8_1 : 48|8@1- (1,0) [0|0] "" Vector__XXX
 SG_ S_EXT_0x25B_S32_1 : 0|32@1- (1,0) [0|0] "" Vector__XXX
 SG_ S_EXT_0x25B_S16_1 : 32|16@1- (1,0) [0|0] "" Vector__XXX

BO_ 2147484250 F_EXT_0x25A: 8 REF_ECU
 SG_ S_EXT_0x25A_S8_2 : 56|8@1- (1,0) [0|0] "" Vector__XXX
 SG_ S_EXT_0x25A_S8_1 : 48|8@1- (1,0) [0|0] "" Vector__XXX
 SG_ S_EXT_0x25A_S32_1 : 0|32@1- (1,0) [0|0] "" Vector__XXX
 SG_ S_EXT_0x25A_S16_1 : 32|16@1- (1,0) [0|0] "" Vector__XXX

BO_ 2147484249 F_EXT_0x259: 8 REF_ECU
 SG_ S_EXT_0x259_S8_2 : 56|8@1- (1,0) [0|0] "" Vector__XXX
 SG_ S_EXT_0x259_S8_1 : 48|8@1- (1,0) [0|0] "" Vector__XXX
 SG_ S_EXT_0x259_S32_1 : 0|32@1- (1,0) [0|0] "" Vector__XXX
 SG_ S_EXT_0x259_S16_1 : 32|16@1- (1,0) [0|0] "" Vector__XXX

BO_ 2147484248 F_EXT_0x258: 8 REF_ECU
 SG_ S_EXT_0x258_S8_2 : 56|8@1- (1,0) [0|0] "" Vector__XXX
 SG_ S_EXT_0x258_S8_1 : 48|8@1- (1,0) [0|0] "" Vector__XXX
 SG_ S_EXT_0x258_S32_1 : 0|32@1- (1,0) [0|0] "" Vector__XXX
 SG_ S_EXT_0x258_S16_1 : 32|16@1- (1,0) [0|0] "" Vector__XXX

BO_ 2147484247 F_EXT_0x257: 8 REF_ECU
 SG_ S_EXT_0x257_S8_2 : 56|8@1- (1,0) [0|0] "" Vector__XXX
 SG_ S_EXT_0x257_S8_1 : 48|8@1- (1,0) [0|0] "" Vector__XXX
 SG_ S_EXT_0x257_S32_1 : 0|32@1- (1,0) [0|0] "" Vector__XXX
 SG_ S_EXT_0x257_S16_1 : 32|16@1- (1,0) [0|0] "" Vector__XXX

BO_ 2147484246 F_EXT_0x256: 8 REF_ECU
 SG_ S_EXT_0x256_S8_2 : 56|8@1- (1,0) [0|0] "" Vector__XXX
 SG_ S_EXT_0x256_S8_1 : 48|8@1- (1,0) [0|0] "" Vector__XXX
 SG_ S_EXT_0x256_S32_1 : 0|32@1- (1,0) [0|0] "" Vector__XXX
 SG_ S_EXT_0x256_S16_1 : 32|16@1- (1,0) [0|0] "" Vector__XXX

BO_ 2147484245 F_EXT_0x255: 8 REF_ECU
 SG_ S_EXT_0x255_S8_2 : 56|8@1- (1,0) [0|0] "" Vector__XXX
 SG_ S_EXT_0x255_S8_1 : 48|8@1- (1,0) [0|0] "" Vector__XXX
 SG_ S_EXT_0x255_S32_1 : 0|32@1- (1,0) [0|0] "" Vector__XXX
 SG_ S_EXT_0x255_S16_1 : 32|16@1- (1,0) [0|0] "" Vector__XXX

BO_ 2147484244 F_EXT_0x254: 8 REF_ECU
 SG_ S_EXT_0x254_S8_2 : 56|8@1- (1,0) [0|0] "" Vector__XXX
 SG_ S_EXT_0x254_S8_1 : 48|8@1- (1,0) [0|0] "" Vector__XXX
 SG_ S_EXT_0x254_S32_1 : 0|32@1- (1,0) [0|0] "" Vector__XXX
 SG_ S_EXT_0x254_S16_1 : 32|16@1- (1,0) [0|0] "" Vector__XXX

BO_ 2147484243 F_EXT_0x253: 8 REF_ECU
 SG_ S_EXT_0x253_S8_2 : 56|8@1- (1,0) [0|0] "" Vector__XXX
 SG_ S_EXT_0x253_S8_1 : 48|8@1- (1,0) [0|0] "" Vector__XXX
 SG_ S_EXT_0x253_S32_1 : 0|32@1- (1,0) [0|0] "" Vector__XXX
 SG_ S_EXT_0x253_S16_1 : 32|16@1- (1,0) [0|0] "" Vector__XXX

BO_ 2147484242 F_EXT_0x252: 8 REF_ECU
 SG_ S_EXT_0x252_S8_2 : 56|8@1- (1,0) [0|0] "" Vector__XXX
 SG_ S_EXT_0x252_S8_1 : 48|8@1- (1,0) [0|0] "" Vector__XXX
 SG_ S_EXT_0x252_S32_1 : 0|32@1- (1,0) [0|0] "" Vector__XXX
 SG_ S_EXT_0x252_S16_1 : 32|16@1- (1,0) [0|0] "" Vector__XXX

BO_ 2147484241 F_EXT_0x251: 8 REF_ECU
 SG_ S_EXT_0x251_S8_2 : 56|8@1- (1,0) [0|0] "" Vector__XXX
 SG_ S_EXT_0x251_S8_1 : 48|8@1- (1,0) [0|0] "" Vector__XXX
 SG_ S_EXT_0x251_S32_1 : 0|32@1- (1,0) [0|0] "" Vector__XXX
 SG_ S_EXT_0x251_S16_1 : 32|16@1- (1,0) [0|0] "" Vector__XXX

BO_ 2147484240 F_EXT_0x250: 8 REF_ECU
 SG_ S_EXT_0x250_S8_2 : 56|8@1- (1,0) [0|0] "" Vector__XXX
 SG_ S_EXT_0x250_S8_1 : 48|8@1- (1,0) [0|0] "" Vector__XXX
 SG_ S_EXT_0x250_S32_1 : 0|32@1- (1,0) [0|0] "" Vector__XXX
 SG_ S_EXT_0x250_S16_1 : 32|16@1- (1,0) [0|0] "" Vector__XXX

BO_ 591 F_STD_0x24F: 8 REF_ECU
 SG_ S_STD_0x24F_S8_2 : 56|8@1- (1,0) [0|0] "" Vector__XXX
 SG_ S_STD_0x24F_S8_1 : 48|8@1- (1,0) [0|0] "" Vector__XXX
 SG_ S_STD_0x24F_S32_1 : 0|32@1- (1,0) [0|0] "" Vector__XXX
 SG_ S_STD_0x24F_S16_1 : 32|16@1- (1,0) [0|0] "" Vector__XXX

BO_ 590 F_STD_0x24E: 8 REF_ECU
 SG_ S_STD_0x24E_S8_2 : 56|8@1- (1,0) [0|0] "" Vector__XXX
 SG_ S_STD_0x24E_S8_1 : 48|8@1- (1,0) [0|0] "" Vector__XXX
 SG_ S_STD_0x24E_S32_1 : 0|32@1- (1,0) [0|0] "" Vector__XXX
 SG_ S_STD_0x24E_S16_1 : 32|16@1- (1,0) [0|0] "" Vector__XXX

BO_ 589 F_STD_0x24D: 8 REF_ECU
 SG_ S_STD_0x24D_S8_2 : 56|8@1- (1,0) [0|0] "" Vector__XXX
 SG_ S_STD_0x24D_S8_1 : 48|8@1- (1,0) [0|0] "" Vector__XXX
 SG_ S_STD_0x24D_S32_1 : 0|32@1- (1,0) [0|0] "" Vector__XXX
 SG_ S_STD_0x24D_S16_1 : 32|16@1- (1,0) [0|0] "" Vector__XXX

BO_ 588 F_STD_0x24C: 8 REF_ECU
 SG_ S_STD_0x24C_S8_2 : 56|8@1- (1,0) [0|0] "" Vector__XXX
 SG_ S_STD_0x24C_S8_1 : 48|8@1- (1,0) [0|0] "" Vector__XXX
 SG_ S_STD_0x24C_S32_1 : 0|32@1- (1,0) [0|0] "" Vector__XXX
 SG_ S_STD_0x24C_S16_1 : 32|16@1- (1,0) [0|0] "" Vector__XXX

BO_ 587 F_STD_0x24B: 8 REF_ECU
 SG_ S_STD_0x24B_S8_2 : 56|8@1- (1,0) [0|0] "" Vector__XXX
 SG_ S_STD_0x24B_S8_1 : 48|8@1- (1,0) [0|0] "" Vector__XXX
 SG_ S_STD_0x24B_S32_1 : 0|32@1- (1,0) [0|0] "" Vector__XXX
 SG_ S_STD_0x24B_S16_1 : 32|16@1- (1,0) [0|0] "" Vector__XXX

BO_ 586 F_STD_0x24A: 8 REF_ECU
 SG_ S_STD_0x24A_S8_2 : 56|8@1- (1,0) [0|0] "" Vector__XXX
 SG_ S_STD_0x24A_S8_1 : 48|8@1- (1,0) [0|0] "" Vector__XXX
 SG_ S_STD_0x24A_S32_1 : 0|32@1- (1,0) [0|0] "" Vector__XXX
 SG_ S_STD_0x24A_S16_1 : 32|16@1- (1,0) [0|0] "" Vector__XXX

BO_ 585 F_STD_0x249: 8 REF_ECU
 SG_ S_STD_0x249_S8_2 : 56|8@1- (1,0) [0|0] "" Vector__XXX
 SG_ S_STD_0x249_S8_1 : 48|8@1- (1,0) [0|0] "" Vector__XXX
 SG_ S_STD_0x249_S32_1 : 0|32@1- (1,0) [0|0] "" Vector__XXX
 SG_ S_STD_0x249_S16_1 : 32|16@1- (1,0) [0|0] "" Vector__XXX

BO_ 584 F_STD_0x248: 8 REF_ECU
 SG_ S_STD_0x248_S8_2 : 56|8@1- (1,0) [0|0] "" Vector__XXX
 SG_ S_STD_0x248_S8_1 : 48|8@1- (1,0) [0|0] "" Vector__XXX
 SG_ S_STD_0x248_S32_1 : 0|32@1- (1,0) [0|0] "" Vector__XXX
 SG_ S_STD_0x248_S16_1 : 32|16@1- (1,0) [0|0] "" Vector__XXX

BO_ 583 F_STD_0x247: 8 REF_ECU
 SG_ S_STD_0x247_S8_2 : 56|8@1- (1,0) [0|0] "" Vector__XXX
 SG_ S_STD_0x247_S8_1 : 48|8@1- (1,0) [0|0] "" Vector__XXX
 SG_ S_STD_0x247_S32_1 : 0|32@1- (1,0) [0|0] "" Vector__XXX
 SG_ S_STD_0x247_S16_1 : 32|16@1- (1,0) [0|0] "" Vector__XXX

BO_ 582 F_STD_0x246: 8 REF_ECU
 SG_ S_STD_0x246_S8_2 : 56|8@1- (1,0) [0|0] "" Vector__XXX
 SG_ S_STD_0x246_S8_1 : 48|8@1- (1,0) [0|0] "" Vector__XXX
 SG_ S_STD_0x246_S32_1 : 0|32@1- (1,0) [0|0] "" Vector__XXX
 SG_ S_STD_0x246_S16_1 : 32|16@1- (1,0) [0|0] "" Vector__XXX

BO_ 581 F_STD_0x245: 8 REF_ECU
 SG_ S_STD_0x245_S8_2 : 56|8@1- (1,0) [0|0] "" Vector__XXX
 SG_ S_STD_0x245_S8_1 : 48|8@1- (1,0) [0|0] "" Vector__XXX
 SG_ S_STD_0x245_S32_1 : 0|32@1- (1,0) [0|0] "" Vector__XXX
 SG_ S_STD_0x245_S16_1 : 32|16@1- (1,0) [0|0] "" Vector__XXX

BO_ 580 F_STD_0x244: 8 REF_ECU
 SG_ S_STD_0x244_S8_2 : 56|8@1- (1,0) [0|0] "" Vector__XXX
 SG_ S_STD_0x244_S8_1 : 48|8@1- (1,0) [0|0] "" Vector__XXX
 SG_ S_STD_0x244_S32_1 : 0|32@1- (1,0) [0|0] "" Vector__XXX
 SG_ S_STD_0x244_S16_1 : 32|16@1- (1,0) [0|0] "" Vector__XXX

BO_ 579 F_STD_0x243: 8 REF_ECU
 SG_ S_STD_0x243_S8_2 : 56|8@1- (1,0) [0|0] "" Vector__XXX
 SG_ S_STD_0x243_S8_1 : 48|8@1- (1,0) [0|0] "" Vector__XXX
 SG_ S_STD_0x243_S32_1 : 0|32@1- (1,0) [0|0] "" Vector__XXX
 SG_ S_STD_0x243_S16_1 : 32|16@1- (1,0) [0|0] "" Vector__XXX

BO_ 578 F_STD_0x242: 8 REF_ECU
 SG_ S_STD_0x242_S8_2 : 56|8@1- (1,0) [0|0] "" Vector__XXX
 SG_ S_STD_0x242_S8_1 : 48|8@1- (1,0) [0|0] "" Vector__XXX
 SG_ S_STD_0x242_S32_1 : 0|32@1- (1,0) [0|0] "" Vector__XXX
 SG_ S_STD_0x242_S16_1 : 32|16@1- (1,0) [0|0] "" Vector__XXX

BO_ 577 F_STD_0x241: 8 REF_ECU
 SG_ S_STD_0x241_S8_2 : 56|8@1- (1,0) [0|0] "" Vector__XXX
 SG_ S_STD_0x241_S8_1 : 48|8@1- (1,0) [0|0] "" Vector__XXX
 SG_ S_STD_0x241_S32_1 : 0|32@1- (1,0) [0|0] "" Vector__XXX
 SG_ S_STD_0x241_S16_1 : 32|16@1- (1,0) [0|0] "" Vector__XXX

BO_ 576 F_STD_0x240: 8 REF_ECU
 SG_ S_STD_0x240_S8_2 : 56|8@1- (1,0) [0|0] "" Vector__XXX
 SG_ S_STD_0x240_S8_1 : 48|8@1- (1,0) [0|0] "" Vector__XXX
 SG_ S_STD_0x240_S32_1 : 0|32@1- (1,0) [0|0] "" Vector__XXX
 SG_ S_STD_0x240_S16_1 : 32|16@1- (1,0) [0|0] "" Vector__XXX

BO_ 575 F_STD_0x23F: 8 REF_ECU
 SG_ S_STD_0x23F_S8_2 : 56|8@1- (1,0) [0|0] "" Vector__XXX
 SG_ S_STD_0x23F_S8_1 : 48|8@1- (1,0) [0|0] "" Vector__XXX
 SG_ S_STD_0x23F_S32_1 : 0|32@1- (1,0) [0|0] "" Vector__XXX
 SG_ S_STD_0x23F_S16_1 : 32|16@1- (1,0) [0|0] "" Vector__XXX

BO_ 574 F_STD_0x23E: 8 REF_ECU
 SG_ S_STD_0x23E_S8_2 : 56|8@1- (1,0) [0|0] "" Vector__XXX
 SG_ S_STD_0x23E_S8_1 : 48|8@1- (1,0) [0|0] "" Vector__XXX
 SG_ S_STD_0x23E_S32_1 : 0|32@1- (1,0) [0|0] "" Vector__XXX
 SG_ S_STD_0x23E_S16_1 : 32|16@1- (1,0) [0|0] "" Vector__XXX

BO_ 573 F_STD_0x23D: 8 REF_ECU
 SG_ S_STD_0x23D_S8_2 : 56|8@1- (1,0) [0|0] "" Vector__XXX
 SG_ S_STD_0x23D_S8_1 : 48|8@1- (1,0) [0|0] "" Vector__XXX
 SG_ S_STD_0x23D_S32_1 : 0|32@1- (1,0) [0|0] "" Vector__XXX
 SG_ S_STD_0x23D_S16_1 : 32|16@1- (1,0) [0|0] "" Vector__XXX

BO_ 572 F_STD_0x23C: 8 REF_ECU
 SG_ S_STD_0x23C_S8_2 : 56|8@1- (1,0) [0|0] "" Vector__XXX
 SG_ S_STD_0x23C_S8_1 : 48|8@1- (1,0) [0|0] "" Vector__XXX
 SG_ S_STD_0x23C_S32_1 : 0|32@1- (1,0) [0|0] "" Vector__XXX
 SG_ S_STD_0x23C_S16_1 : 32|16@1- (1,0) [0|0] "" Vector__XXX

BO_ 571 F_STD_0x23B: 8 REF_ECU
 SG_ S_STD_0x23B_S8_2 : 56|8@1- (1,0) [0|0] "" Vector__XXX
 SG_ S_STD_0x23B_S8_1 : 48|8@1- (1,0) [0|0] "" Vector__XXX
 SG_ S_STD_0x23B_S32_1 : 0|32@1- (1,0) [0|0] "" Vector__XXX
 SG_ S_STD_0x23B_S16_1 : 32|16@1- (1,0) [0|0] "" Vector__XXX

BO_ 570 F_STD_0x23A: 8 REF_ECU
 SG_ S_STD_0x23A_S8_2 : 56|8@1- (1,0) [0|0] "" Vector__XXX
 SG_ S_STD_0x23A_S8_1 : 48|8@1- (1,0) [0|0] "" Vector__XXX
 SG_ S_STD_0x23A_S32_1 : 0|32@1- (1,0) [0|0] "" Vector__XXX
 SG_ S_STD_0x23A_S16_1 : 32|16@1- (1,0) [0|0] "" Vector__XXX

BO_ 569 F_STD_0x239: 8 REF_ECU
 SG_ S_STD_0x239_S8_2 : 56|8@1- (1,0) [0|0] "" Vector__XXX
 SG_ S_STD_0x239_S8_1 : 48|8@1- (1,0) [0|0] "" Vector__XXX
 SG_ S_STD_0x239_S32_1 : 0|32@1- (1,0) [0|0] "" Vector__XXX
 SG_ S_STD_0x239_S16_1 : 32|16@1- (1,0) [0|0] "" Vector__XXX

BO_ 568 F_STD_0x238: 8 REF_ECU
 SG_ S_STD_0x238_S8_2 : 56|8@1- (1,0) [0|0] "" Vector__XXX
 SG_ S_STD_0x238_S8_1 : 48|8@1- (1,0) [0|0] "" Vector__XXX
 SG_ S_STD_0x238_S32_1 : 0|32@1- (1,0) [0|0] "" Vector__XXX
 SG_ S_STD_0x238_S16_1 : 32|16@1- (1,0) [0|0] "" Vector__XXX

BO_ 567 F_STD_0x237: 8 REF_ECU
 SG_ S_STD_0x237_S8_2 : 56|8@1- (1,0) [0|0] "" Vector__XXX
 SG_ S_STD_0x237_S8_1 : 48|8@1- (1,0) [0|0] "" Vector__XXX
 SG_ S_STD_0x237_S32_1 : 0|32@1- (1,0) [0|0] "" Vector__XXX
 SG_ S_STD_0x237_S16_1 : 32|16@1- (1,0) [0|0] "" Vector__XXX

BO_ 566 F_STD_0x236: 8 REF_ECU
 SG_ S_STD_0x236_S8_2 : 56|8@1- (1,0) [0|0] "" Vector__XXX
 SG_ S_STD_0x236_S8_1 : 48|8@1- (1,0) [0|0] "" Vector__XXX
 SG_ S_STD_0x236_S32_1 : 0|32@1- (1,0) [0|0] "" Vector__XXX
 SG_ S_STD_0x236_S16_1 : 32|16@1- (1,0) [0|0] "" Vector__XXX

BO_ 565 F_STD_0x235: 8 REF_ECU
 SG_ S_STD_0x235_S8_2 : 56|8@1- (1,0) [0|0] "" Vector__XXX
 SG_ S_STD_0x235_S8_1 : 48|8@1- (1,0) [0|0] "" Vector__XXX
 SG_ S_STD_0x235_S32_1 : 0|32@1- (1,0) [0|0] "" Vector__XXX
 SG_ S_STD_0x235_S16_1 : 32|16@1- (1,0) [0|0] "" Vector__XXX

BO_ 564 F_STD_0x234: 8 REF_ECU
 SG_ S_STD_0x234_S8_2 : 56|8@1- (1,0) [0|0] "" Vector__XXX
 SG_ S_STD_0x234_S8_1 : 48|8@1- (1,0) [0|0] "" Vector__XXX
 SG_ S_STD_0x234_S32_1 : 0|32@1- (1,0) [0|0] "" Vector__XXX
 SG_ S_STD_0x234_S16_1 : 32|16@1- (1,0) [0|0] "" Vector__XXX

BO_ 563 F_STD_0x233: 8 REF_ECU
 SG_ S_STD_0x233_S8_2 : 56|8@1- (1,0) [0|0] "" Vector__XXX
 SG_ S_STD_0x233_S8_1 : 48|8@1- (1,0) [0|0] "" Vector__XXX
 SG_ S_STD_0x233_S32_1 : 0|32@1- (1,0) [0|0] "" Vector__XXX
 SG_ S_STD_0x233_S16_1 : 32|16@1- (1,0) [0|0] "" Vector__XXX

BO_ 562 F_STD_0x232: 8 REF_ECU
 SG_ S_STD_0x232_S8_2 : 56|8@1- (1,0) [0|0] "" Vector__XXX
 SG_ S_STD_0x232_S8_1 : 48|8@1- (1,0) [0|0] "" Vector__XXX
 SG_ S_STD_0x232_S32_1 : 0|32@1- (1,0) [0|0] "" Vector__XXX
 SG_ S_STD_0x232_S16_1 : 32|16@1- (1,0) [0|0] "" Vector__XXX

BO_ 561 F_STD_0x231: 8 REF_ECU
 SG_ S_STD_0x231_S8_2 : 56|8@1- (1,0) [0|0] "" Vector__XXX
 SG_ S_STD_0x231_S8_1 : 48|8@1- (1,0) [0|0] "" Vector__XXX
 SG_ S_STD_0x231_S32_1 : 0|32@1- (1,0) [0|0] "" Vector__XXX
 SG_ S_STD_0x231_S16_1 : 32|16@1- (1,0) [0|0] "" Vector__XXX

BO_ 560 F_STD_0x230: 8 REF_ECU
 SG_ S_STD_0x230_S8_2 : 56|8@1- (1,0) [0|0] "" Vector__XXX
 SG_ S_STD_0x230_S8_1 : 48|8@1- (1,0) [0|0] "" Vector__XXX
 SG_ S_STD_0x230_S32_1 : 0|32@1- (1,0) [0|0] "" Vector__XXX
 SG_ S_STD_0x230_S16_1 : 32|16@1- (1,0) [0|0] "" Vector__XXX

BO_ 559 F_STD_0x22F: 8 REF_ECU
 SG_ S_STD_0x22F_S8_2 : 56|8@1- (1,0) [0|0] "" Vector__XXX
 SG_ S_STD_0x22F_S8_1 : 48|8@1- (1,0) [0|0] "" Vector__XXX
 SG_ S_STD_0x22F_S32_1 : 0|32@1- (1,0) [0|0] "" Vector__XXX
 SG_ S_STD_0x22F_S16_1 : 32|16@1- (1,0) [0|0] "" Vector__XXX

BO_ 558 F_STD_0x22E: 8 REF_ECU
 SG_ S_STD_0x22E_S8_2 : 56|8@1- (1,0) [0|0] "" Vector__XXX
 SG_ S_STD_0x22E_S8_1 : 48|8@1- (1,0) [0|0] "" Vector__XXX
 SG_ S_STD_0x22E_S32_1 : 0|32@1- (1,0) [0|0] "" Vector__XXX
 SG_ S_STD_0x22E_S16_1 : 32|16@1- (1,0) [0|0] "" Vector__XXX

BO_ 557 F_STD_0x22D: 8 REF_ECU
 SG_ S_STD_0x22D_S8_2 : 56|8@1- (1,0) [0|0] "" Vector__XXX
 SG_ S_STD_0x22D_S8_1 : 48|8@1- (1,0) [0|0] "" Vector__XXX
 SG_ S_STD_0x22D_S32_1 : 0|32@1- (1,0) [0|0] "" Vector__XXX
 SG_ S_STD_0x22D_S16_1 : 32|16@1- (1,0) [0|0] "" Vector__XXX

BO_ 556 F_STD_0x22C: 8 REF_ECU
 SG_ S_STD_0x22C_S8_2 : 56|8@1- (1,0) [0|0] "" Vector__XXX
 SG_ S_STD_0x22C_S8_1 : 48|8@1- (1,0) [0|0] "" Vector__XXX
 SG_ S_STD_0x22C_S32_1 : 0|32@1- (1,0) [0|0] "" Vector__XXX
 SG_ S_STD_0x22C_S16_1 : 32|16@1- (1,0) [0|0] "" Vector__XXX

BO_ 555 F_STD_0x22B: 8 REF_ECU
 SG_ S_STD_0x22B_S8_2 : 56|8@1- (1,0) [0|0] "" Vector__XXX
 SG_ S_STD_0x22B_S8_1 : 48|8@1- (1,0) [0|0] "" Vector__XXX
 SG_ S_STD_0x22B_S32_1 : 0|32@1- (1,0) [0|0] "" Vector__XXX
 SG_ S_STD_0x22B_S16_1 : 32|16@1- (1,0) [0|0] "" Vector__XXX

BO_ 554 F_STD_0x22A: 8 REF_ECU
 SG_ S_STD_0x22A_S8_2 : 56|8@1- (1,0) [0|0] "" Vector__XXX
 SG_ S_STD_0x22A_S8_1 : 48|8@1- (1,0) [0|0] "" Vector__XXX
 SG_ S_STD_0x22A_S32_1 : 0|32@1- (1,0) [0|0] "" Vector__XXX
 SG_ S_STD_0x22A_S16_1 : 32|16@1- (1,0) [0|0] "" Vector__XXX

BO_ 553 F_STD_0x229: 8 REF_ECU
 SG_ S_STD_0x229_S8_2 : 56|8@1- (1,0) [0|0] "" Vector__XXX
 SG_ S_STD_0x229_S8_1 : 48|8@1- (1,0) [0|0] "" Vector__XXX
 SG_ S_STD_0x229_S32_1 : 0|32@1- (1,0) [0|0] "" Vector__XXX
 SG_ S_STD_0x229_S16_1 : 32|16@1- (1,0) [0|0] "" Vector__XXX

BO_ 552 F_STD_0x228: 8 REF_ECU
 SG_ S_STD_0x228_S8_2 : 56|8@1- (1,0) [0|0] "" Vector__XXX
 SG_ S_STD_0x228_S8_1 : 48|8@1- (1,0) [0|0] "" Vector__XXX
 SG_ S_STD_0x228_S32_1 : 0|32@1- (1,0) [0|0] "" Vector__XXX
 SG_ S_STD_0x228_S16_1 : 32|16@1- (1,0) [0|0] "" Vector__XXX

BO_ 551 F_STD_0x227: 8 REF_ECU
 SG_ S_STD_0x227_S8_2 : 56|8@1- (1,0) [0|0] "" Vector__XXX
 SG_ S_STD_0x227_S8_1 : 48|8@1- (1,0) [0|0] "" Vector__XXX
 SG_ S_STD_0x227_S32_1 : 0|32@1- (1,0) [0|0] "" Vector__XXX
 SG_ S_STD_0x227_S16_1 : 32|16@1- (1,0) [0|0] "" Vector__XXX

BO_ 550 F_STD_0x226: 8 REF_ECU
 SG_ S_STD_0x226_S8_2 : 56|8@1- (1,0) [0|0] "" Vector__XXX
 SG_ S_STD_0x226_S8_1 : 48|8@1- (1,0) [0|0] "" Vector__XXX
 SG_ S_STD_0x226_S32_1 : 0|32@1- (1,0) [0|0] "" Vector__XXX
 SG_ S_STD_0x226_S16_1 : 32|16@1- (1,0) [0|0] "" Vector__XXX

BO_ 549 F_STD_0x225: 8 REF_ECU
 SG_ S_STD_0x225_S8_2 : 56|8@1- (1,0) [0|0] "" Vector__XXX
 SG_ S_STD_0x225_S8_1 : 48|8@1- (1,0) [0|0] "" Vector__XXX
 SG_ S_STD_0x225_S32_1 : 0|32@1- (1,0) [0|0] "" Vector__XXX
 SG_ S_STD_0x225_S16_1 : 32|16@1- (1,0) [0|0] "" Vector__XXX

BO_ 548 F_STD_0x224: 8 REF_ECU
 SG_ S_STD_0x224_S8_2 : 56|8@1- (1,0) [0|0] "" Vector__XXX
 SG_ S_STD_0x224_S8_1 : 48|8@1- (1,0) [0|0] "" Vector__XXX
 SG_ S_STD_0x224_S32_1 : 0|32@1- (1,0) [0|0] "" Vector__XXX
 SG_ S_STD_0x224_S16_1 : 32|16@1- (1,0) [0|0] "" Vector__XXX

BO_ 547 F_STD_0x223: 8 REF_ECU
 SG_ S_STD_0x223_S8_2 : 56|8@1- (1,0) [0|0] "" Vector__XXX
 SG_ S_STD_0x223_S8_1 : 48|8@1- (1,0) [0|0] "" Vector__XXX
 SG_ S_STD_0x223_S32_1 : 0|32@1- (1,0) [0|0] "" Vector__XXX
 SG_ S_STD_0x223_S16_1 : 32|16@1- (1,0) [0|0] "" Vector__XXX

BO_ 546 F_STD_0x222: 8 REF_ECU
 SG_ S_STD_0x222_S8_2 : 56|8@1- (1,0) [0|0] "" Vector__XXX
 SG_ S_STD_0x222_S8_1 : 48|8@1- (1,0) [0|0] "" Vector__XXX
 SG_ S_STD_0x222_S32_1 : 0|32@1- (1,0) [0|0] "" Vector__XXX
 SG_ S_STD_0x222_S16_1 : 32|16@1- (1,0) [0|0] "" Vector__XXX

BO_ 545 F_STD_0x221: 8 REF_ECU
 SG_ S_STD_0x221_S8_2 : 56|8@1- (1,0) [0|0] "" Vector__XXX
 SG_ S_STD_0x221_S8_1 : 48|8@1- (1,0) [0|0] "" Vector__XXX
 SG_ S_STD_0x221_S32_1 : 0|32@1- (1,0) [0|0] "" Vector__XXX
 SG_ S_STD_0x221_S16_1 : 32|16@1- (1,0) [0|0] "" Vector__XXX

BO_ 544 F_STD_0x220: 8 REF_ECU
 SG_ S_STD_0x220_S8_2 : 56|8@1- (1,0) [0|0] "" Vector__XXX
 SG_ S_STD_0x220_S8_1 : 48|8@1- (1,0) [0|0] "" Vector__XXX
 SG_ S_STD_0x220_S32_1 : 0|32@1- (1,0) [0|0] "" Vector__XXX
 SG_ S_STD_0x220_S16_1 : 32|16@1- (1,0) [0|0] "" Vector__XXX

BO_ 543 F_STD_0x21F: 8 REF_ECU
 SG_ S_STD_0x21F_S8_2 : 56|8@1- (1,0) [0|0] "" Vector__XXX
 SG_ S_STD_0x21F_S8_1 : 48|8@1- (1,0) [0|0] "" Vector__XXX
 SG_ S_STD_0x21F_S32_1 : 0|32@1- (1,0) [0|0] "" Vector__XXX
 SG_ S_STD_0x21F_S16_1 : 32|16@1- (1,0) [0|0] "" Vector__XXX

BO_ 542 F_STD_0x21E: 8 REF_ECU
 SG_ S_STD_0x21E_S8_2 : 56|8@1- (1,0) [0|0] "" Vector__XXX
 SG_ S_STD_0x21E_S8_1 : 48|8@1- (1,0) [0|0] "" Vector__XXX
 SG_ S_STD_0x21E_S32_1 : 0|32@1- (1,0) [0|0] "" Vector__XXX
 SG_ S_STD_0x21E_S16_1 : 32|16@1- (1,0) [0|0] "" Vector__XXX

BO_ 541 F_STD_0x21D: 8 REF_ECU
 SG_ S_STD_0x21D_S8_2 : 56|8@1- (1,0) [0|0] "" Vector__XXX
 SG_ S_STD_0x21D_S8_1 : 48|8@1- (1,0) [0|0] "" Vector__XXX
 SG_ S_STD_0x21D_S32_1 : 0|32@1- (1,0) [0|0] "" Vector__XXX
 SG_ S_STD_0x21D_S16_1 : 32|16@1- (1,0) [0|0] "" Vector__XXX

BO_ 540 F_STD_0x21C: 8 REF_ECU
 SG_ S_STD_0x21C_S8_2 : 56|8@1- (1,0) [0|0] "" Vector__XXX
 SG_ S_STD_0x21C_S8_1 : 48|8@1- (1,0) [0|0] "" Vector__XXX
 SG_ S_STD_0x21C_S32_1 : 0|32@1- (1,0) [0|0] "" Vector__XXX
 SG_ S_STD_0x21C_S16_1 : 32|16@1- (1,0) [0|0] "" Vector__XXX

BO_ 539 F_STD_0x21B: 8 REF_ECU
 SG_ S_STD_0x21B_S8_2 : 56|8@1- (1,0) [0|0] "" Vector__XXX
 SG_ S_STD_0x21B_S8_1 : 48|8@1- (1,0) [0|0] "" Vector__XXX
 SG_ S_STD_0x21B_S32_1 : 0|32@1- (1,0) [0|0] "" Vector__XXX
 SG_ S_STD_0x21B_S16_1 : 32|16@1- (1,0) [0|0] "" Vector__XXX

BO_ 538 F_STD_0x21A: 8 REF_ECU
 SG_ S_STD_0x21A_S8_2 : 56|8@1- (1,0) [0|0] "" Vector__XXX
 SG_ S_STD_0x21A_S8_1 : 48|8@1- (1,0) [0|0] "" Vector__XXX
 SG_ S_STD_0x21A_S32_1 : 0|32@1- (1,0) [0|0] "" Vector__XXX
 SG_ S_STD_0x21A_S16_1 : 32|16@1- (1,0) [0|0] "" Vector__XXX

BO_ 537 F_STD_0x219: 8 REF_ECU
 SG_ S_STD_0x219_S8_2 : 56|8@1- (1,0) [0|0] "" Vector__XXX
 SG_ S_STD_0x219_S8_1 : 48|8@1- (1,0) [0|0] "" Vector__XXX
 SG_ S_STD_0x219_S32_1 : 0|32@1- (1,0) [0|0] "" Vector__XXX
 SG_ S_STD_0x219_S16_1 : 32|16@1- (1,0) [0|0] "" Vector__XXX

BO_ 536 F_STD_0x218: 8 REF_ECU
 SG_ S_STD_0x218_S8_2 : 56|8@1- (1,0) [0|0] "" Vector__XXX
 SG_ S_STD_0x218_S8_1 : 48|8@1- (1,0) [0|0] "" Vector__XXX
 SG_ S_STD_0x218_S32_1 : 0|32@1- (1,0) [0|0] "" Vector__XXX
 SG_ S_STD_0x218_S16_1 : 32|16@1- (1,0) [0|0] "" Vector__XXX

BO_ 535 F_STD_0x217: 8 REF_ECU
 SG_ S_STD_0x217_S8_2 : 56|8@1- (1,0) [0|0] "" Vector__XXX
 SG_ S_STD_0x217_S8_1 : 48|8@1- (1,0) [0|0] "" Vector__XXX
 SG_ S_STD_0x217_S32_1 : 0|32@1- (1,0) [0|0] "" Vector__XXX
 SG_ S_STD_0x217_S16_1 : 32|16@1- (1,0) [0|0] "" Vector__XXX

BO_ 534 F_STD_0x216: 8 REF_ECU
 SG_ S_STD_0x216_S8_2 : 56|8@1- (1,0) [0|0] "" Vector__XXX
 SG_ S_STD_0x216_S8_1 : 48|8@1- (1,0) [0|0] "" Vector__XXX
 SG_ S_STD_0x216_S32_1 : 0|32@1- (1,0) [0|0] "" Vector__XXX
 SG_ S_STD_0x216_S16_1 : 32|16@1- (1,0) [0|0] "" Vector__XXX

BO_ 533 F_STD_0x215: 8 REF_ECU
 SG_ S_STD_0x215_S8_2 : 56|8@1- (1,0) [0|0] "" Vector__XXX
 SG_ S_STD_0x215_S8_1 : 48|8@1- (1,0) [0|0] "" Vector__XXX
 SG_ S_STD_0x215_S32_1 : 0|32@1- (1,0) [0|0] "" Vector__XXX
 SG_ S_STD_0x215_S16_1 : 32|16@1- (1,0) [0|0] "" Vector__XXX

BO_ 532 F_STD_0x214: 8 REF_ECU
 SG_ S_STD_0x214_S8_2 : 56|8@1- (1,0) [0|0] "" Vector__XXX
 SG_ S_STD_0x214_S8_1 : 48|8@1- (1,0) [0|0] "" Vector__XXX
 SG_ S_STD_0x214_S32_1 : 0|32@1- (1,0) [0|0] "" Vector__XXX
 SG_ S_STD_0x214_S16_1 : 32|16@1- (1,0) [0|0] "" Vector__XXX

BO_ 531 F_STD_0x213: 8 REF_ECU
 SG_ S_STD_0x213_S8_2 : 56|8@1- (1,0) [0|0] "" Vector__XXX
 SG_ S_STD_0x213_S8_1 : 48|8@1- (1,0) [0|0] "" Vector__XXX
 SG_ S_STD_0x213_S32_1 : 0|32@1- (1,0) [0|0] "" Vector__XXX
 SG_ S_STD_0x213_S16_1 : 32|16@1- (1,0) [0|0] "" Vector__XXX

BO_ 530 F_STD_0x212: 8 REF_ECU
 SG_ S_STD_0x212_S8_2 : 56|8@1- (1,0) [0|0] "" Vector__XXX
 SG_ S_STD_0x212_S8_1 : 48|8@1- (1,0) [0|0] "" Vector__XXX
 SG_ S_STD_0x212_S32_1 : 0|32@1- (1,0) [0|0] "" Vector__XXX
 SG_ S_STD_0x212_S16_1 : 32|16@1- (1,0) [0|0] "" Vector__XXX

BO_ 529 F_STD_0x211: 8 REF_ECU
 SG_ S_STD_0x211_S8_2 : 56|8@1- (1,0) [0|0] "" Vector__XXX
 SG_ S_STD_0x211_S8_1 : 48|8@1- (1,0) [0|0] "" Vector__XXX
 SG_ S_STD_0x211_S32_1 : 0|32@1- (1,0) [0|0] "" Vector__XXX
 SG_ S_STD_0x211_S16_1 : 32|16@1- (1,0) [0|0] "" Vector__XXX

BO_ 528 F_STD_0x210: 8 REF_ECU
 SG_ S_STD_0x210_S8_2 : 56|8@1- (1,0) [0|0] "" Vector__XXX
 SG_ S_STD_0x210_S8_1 : 48|8@1- (1,0) [0|0] "" Vector__XXX
 SG_ S_STD_0x210_S32_1 : 0|32@1- (1,0) [0|0] "" Vector__XXX
 SG_ S_STD_0x210_S16_1 : 32|16@1- (1,0) [0|0] "" Vector__XXX

BO_ 527 F_STD_0x20F: 8 REF_ECU
 SG_ S_STD_0x20F_S8_2 : 56|8@1- (1,0) [0|0] "" Vector__XXX
 SG_ S_STD_0x20F_S8_1 : 48|8@1- (1,0) [0|0] "" Vector__XXX
 SG_ S_STD_0x20F_S32_1 : 0|32@1- (1,0) [0|0] "" Vector__XXX
 SG_ S_STD_0x20F_S16_1 : 32|16@1- (1,0) [0|0] "" Vector__XXX

BO_ 526 F_STD_0x20E: 8 REF_ECU
 SG_ S_STD_0x20E_S8_2 : 56|8@1- (1,0) [0|0] "" Vector__XXX
 SG_ S_STD_0x20E_S8_1 : 48|8@1- (1,0) [0|0] "" Vector__XXX
 SG_ S_STD_0x20E_S32_1 : 0|32@1- (1,0) [0|0] "" Vector__XXX
 SG_ S_STD_0x20E_S16_1 : 32|16@1- (1,0) [0|0] "" Vector__XXX

BO_ 525 F_STD_0x20D: 8 REF_ECU
 SG_ S_STD_0x20D_S8_2 : 56|8@1- (1,0) [0|0] "" Vector__XXX
 SG_ S_STD_0x20D_S8_1 : 48|8@1- (1,0) [0|0] "" Vector__XXX
 SG_ S_STD_0x20D_S32_1 : 0|32@1- (1,0) [0|0] "" Vector__XXX
 SG_ S_STD_0x20D_S16_1 : 32|16@1- (1,0) [0|0] "" Vector__XXX

BO_ 524 F_STD_0x20C: 8 REF_ECU
 SG_ S_STD_0x20C_S8_2 : 56|8@1- (1,0) [0|0] "" Vector__XXX
 SG_ S_STD_0x20C_S8_1 : 48|8@1- (1,0) [0|0] "" Vector__XXX
 SG_ S_STD_0x20C_S32_1 : 0|32@1- (1,0) [0|0] "" Vector__XXX
 SG_ S_STD_0x20C_S16_1 : 32|16@1- (1,0) [0|0] "" Vector__XXX

BO_ 523 F_STD_0x20B: 8 REF_ECU
 SG_ S_STD_0x20B_S8_2 : 56|8@1- (1,0) [0|0] "" Vector__XXX
 SG_ S_STD_0x20B_S8_1 : 48|8@1- (1,0) [0|0] "" Vector__XXX
 SG_ S_STD_0x20B_S32_1 : 0|32@1- (1,0) [0|0] "" Vector__XXX
 SG_ S_STD_0x20B_S16_1 : 32|16@1- (1,0) [0|0] "" Vector__XXX

BO_ 522 F_STD_0x20A: 8 REF_ECU
 SG_ S_STD_0x20A_S8_2 : 56|8@1- (1,0) [0|0] "" Vector__XXX
 SG_ S_STD_0x20A_S8_1 : 48|8@1- (1,0) [0|0] "" Vector__XXX
 SG_ S_STD_0x20A_S32_1 : 0|32@1- (1,0) [0|0] "" Vector__XXX
 SG_ S_STD_0x20A_S16_1 : 32|16@1- (1,0) [0|0] "" Vector__XXX

BO_ 521 F_STD_0x209: 8 REF_ECU
 SG_ S_STD_0x209_S8_2 : 56|8@1- (1,0) [0|0] "" Vector__XXX
 SG_ S_STD_0x209_S8_1 : 48|8@1- (1,0) [0|0] "" Vector__XXX
 SG_ S_STD_0x209_S32_1 : 0|32@1- (1,0) [0|0] "" Vector__XXX
 SG_ S_STD_0x209_S16_1 : 32|16@1- (1,0) [0|0] "" Vector__XXX

BO_ 520 F_STD_0x208: 8 REF_ECU
 SG_ S_STD_0x208_S8_2 : 56|8@1- (1,0) [0|0] "" Vector__XXX
 SG_ S_STD_0x208_S8_1 : 48|8@1- (1,0) [0|0] "" Vector__XXX
 SG_ S_STD_0x208_S32_1 : 0|32@1- (1,0) [0|0] "" Vector__XXX
 SG_ S_STD_0x208_S16_1 : 32|16@1- (1,0) [0|0] "" Vector__XXX

BO_ 519 F_STD_0x207: 8 REF_ECU
 SG_ S_STD_0x207_S8_2 : 56|8@1- (1,0) [0|0] "" Vector__XXX
 SG_ S_STD_0x207_S8_1 : 48|8@1- (1,0) [0|0] "" Vector__XXX
 SG_ S_STD_0x207_S32_1 : 0|32@1- (1,0) [0|0] "" Vector__XXX
 SG_ S_STD_0x207_S16_1 : 32|16@1- (1,0) [0|0] "" Vector__XXX

BO_ 518 F_STD_0x206: 8 REF_ECU
 SG_ S_STD_0x206_S8_2 : 56|8@1- (1,0) [0|0] "" Vector__XXX
 SG_ S_STD_0x206_S8_1 : 48|8@1- (1,0) [0|0] "" Vector__XXX
 SG_ S_STD_0x206_S32_1 : 0|32@1- (1,0) [0|0] "" Vector__XXX
 SG_ S_STD_0x206_S16_1 : 32|16@1- (1,0) [0|0] "" Vector__XXX

BO_ 517 F_STD_0x205: 8 REF_ECU
 SG_ S_STD_0x205_S8_2 : 56|8@1- (1,0) [0|0] "" Vector__XXX
 SG_ S_STD_0x205_S8_1 : 48|8@1- (1,0) [0|0] "" Vector__XXX
 SG_ S_STD_0x205_S32_1 : 0|32@1- (1,0) [0|0] "" Vector__XXX
 SG_ S_STD_0x205_S16_1 : 32|16@1- (1,0) [0|0] "" Vector__XXX

BO_ 516 F_STD_0x204: 8 REF_ECU
 SG_ S_STD_0x204_S8_2 : 56|8@1- (1,0) [0|0] "" Vector__XXX
 SG_ S_STD_0x204_S8_1 : 48|8@1- (1,0) [0|0] "" Vector__XXX
 SG_ S_STD_0x204_S32_1 : 0|32@1- (1,0) [0|0] "" Vector__XXX
 SG_ S_STD_0x204_S16_1 : 32|16@1- (1,0) [0|0] "" Vector__XXX

BO_ 515 F_STD_0x203: 8 REF_ECU
 SG_ S_STD_0x203_S8_2 : 56|8@1- (1,0) [0|0] "" Vector__XXX
 SG_ S_STD_0x203_S8_1 : 48|8@1- (1,0) [0|0] "" Vector__XXX
 SG_ S_STD_0x203_S32_1 : 0|32@1- (1,0) [0|0] "" Vector__XXX
 SG_ S_STD_0x203_S16_1 : 32|16@1- (1,0) [0|0] "" Vector__XXX

BO_ 514 F_STD_0x202: 8 REF_ECU
 SG_ S_STD_0x202_S8_2 : 56|8@1- (1,0) [0|0] "" Vector__XXX
 SG_ S_STD_0x202_S8_1 : 48|8@1- (1,0) [0|0] "" Vector__XXX
 SG_ S_STD_0x202_S32_1 : 0|32@1- (1,0) [0|0] "" Vector__XXX
 SG_ S_STD_0x202_S16_1 : 32|16@1- (1,0) [0|0] "" Vector__XXX

BO_ 513 F_STD_0x201: 8 REF_ECU
 SG_ S_STD_0x201_S8_2 : 56|8@1- (1,0) [0|0] "" Vector__XXX
 SG_ S_STD_0x201_S8_1 : 48|8@1- (1,0) [0|0] "" Vector__XXX
 SG_ S_STD_0x201_S32_1 : 0|32@1- (1,0) [0|0] "" Vector__XXX
 SG_ S_STD_0x201_S16_1 : 32|16@1- (1,0) [0|0] "" Vector__XXX

BO_ 512 F_STD_0x200: 8 REF_ECU
 SG_ S_STD_0x200_S8_2 : 56|8@1- (1,0) [0|0] "" Vector__XXX
 SG_ S_STD_0x200_S8_1 : 48|8@1- (1,0) [0|0] "" Vector__XXX
 SG_ S_STD_0x200_S32_1 : 0|32@1- (1,0) [0|0] "" Vector__XXX
 SG_ S_STD_0x200_S16_1 : 32|16@1- (1,0) [0|0] "" Vector__XXX

BO_ 2147484063 F_EXT_0x19F: 8 REF_ECU
 SG_ S_EXT_0x19F_S8_2 : 56|8@1- (1,0) [0|0] "" Vector__XXX
 SG_ S_EXT_0x19F_S8_1 : 48|8@1- (1,0) [0|0] "" Vector__XXX
 SG_ S_EXT_0x19F_S32_1 : 0|32@1- (1,0) [0|0] "" Vector__XXX
 SG_ S_EXT_0x19F_S16_1 : 32|16@1- (1,0) [0|0] "" Vector__XXX

BO_ 2147484062 F_EXT_0x19E: 8 REF_ECU
 SG_ S_EXT_0x19E_S8_2 : 56|8@1- (1,0) [0|0] "" Vector__XXX
 SG_ S_EXT_0x19E_S8_1 : 48|8@1- (1,0) [0|0] "" Vector__XXX
 SG_ S_EXT_0x19E_S32_1 : 0|32@1- (1,0) [0|0] "" Vector__XXX
 SG_ S_EXT_0x19E_S16_1 : 32|16@1- (1,0) [0|0] "" Vector__XXX

BO_ 2147484061 F_EXT_0x19D: 8 REF_ECU
 SG_ S_EXT_0x19D_S8_2 : 56|8@1- (1,0) [0|0] "" Vector__XXX
 SG_ S_EXT_0x19D_S8_1 : 48|8@1- (1,0) [0|0] "" Vector__XXX
 SG_ S_EXT_0x19D_S32_1 : 0|32@1- (1,0) [0|0] "" Vector__XXX
 SG_ S_EXT_0x19D_S16_1 : 32|16@1- (1,0) [0|0] "" Vector__XXX

BO_ 2147484060 F_EXT_0x19C: 8 REF_ECU
 SG_ S_EXT_0x19C_S8_2 : 56|8@1- (1,0) [0|0] "" Vector__XXX
 SG_ S_EXT_0x19C_S8_1 : 48|8@1- (1,0) [0|0] "" Vector__XXX
 SG_ S_EXT_0x19C_S32_1 : 0|32@1- (1,0) [0|0] "" Vector__XXX
 SG_ S_EXT_0x19C_S16_1 : 32|16@1- (1,0) [0|0] "" Vector__XXX

BO_ 2147484059 F_EXT_0x19B: 8 REF_ECU
 SG_ S_EXT_0x19B_S8_2 : 56|8@1- (1,0) [0|0] "" Vector__XXX
 SG_ S_EXT_0x19B_S8_1 : 48|8@1- (1,0) [0|0] "" Vector__XXX
 SG_ S_EXT_0x19B_S32_1 : 0|32@1- (1,0) [0|0] "" Vector__XXX
 SG_ S_EXT_0x19B_S16_1 : 32|16@1- (1,0) [0|0] "" Vector__XXX

BO_ 2147484058 F_EXT_0x19A: 8 REF_ECU
 SG_ S_EXT_0x19A_S8_2 : 56|8@1- (1,0) [0|0] "" Vector__XXX
 SG_ S_EXT_0x19A_S8_1 : 48|8@1- (1,0) [0|0] "" Vector__XXX
 SG_ S_EXT_0x19A_S32_1 : 0|32@1- (1,0) [0|0] "" Vector__XXX
 SG_ S_EXT_0x19A_S16_1 : 32|16@1- (1,0) [0|0] "" Vector__XXX

BO_ 2147484057 F_EXT_0x199: 8 REF_ECU
 SG_ S_EXT_0x199_S8_2 : 56|8@1- (1,0) [0|0] "" Vector__XXX
 SG_ S_EXT_0x199_S8_1 : 48|8@1- (1,0) [0|0] "" Vector__XXX
 SG_ S_EXT_0x199_S32_1 : 0|32@1- (1,0) [0|0] "" Vector__XXX
 SG_ S_EXT_0x199_S16_1 : 32|16@1- (1,0) [0|0] "" Vector__XXX

BO_ 2147484056 F_EXT_0x198: 8 REF_ECU
 SG_ S_EXT_0x198_S8_2 : 56|8@1- (1,0) [0|0] "" Vector__XXX
 SG_ S_EXT_0x198_S8_1 : 48|8@1- (1,0) [0|0] "" Vector__XXX
 SG_ S_EXT_0x198_S32_1 : 0|32@1- (1,0) [0|0] "" Vector__XXX
 SG_ S_EXT_0x198_S16_1 : 32|16@1- (1,0) [0|0] "" Vector__XXX

BO_ 2147484055 F_EXT_0x197: 8 REF_ECU
 SG_ S_EXT_0x197_S8_2 : 56|8@1- (1,0) [0|0] "" Vector__XXX
 SG_ S_EXT_0x197_S8_1 : 48|8@1- (1,0) [0|0] "" Vector__XXX
 SG_ S_EXT_0x197_S32_1 : 0|32@1- (1,0) [0|0] "" Vector__XXX
 SG_ S_EXT_0x197_S16_1 : 32|16@1- (1,0) [0|0] "" Vector__XXX

BO_ 2147484054 F_EXT_0x196: 8 REF_ECU
 SG_ S_EXT_0x196_S8_2 : 56|8@1- (1,0) [0|0] "" Vector__XXX
 SG_ S_EXT_0x196_S8_1 : 48|8@1- (1,0) [0|0] "" Vector__XXX
 SG_ S_EXT_0x196_S32_1 : 0|32@1- (1,0) [0|0] "" Vector__XXX
 SG_ S_EXT_0x196_S16_1 : 32|16@1- (1,0) [0|0] "" Vector__XXX

BO_ 2147484053 F_EXT_0x195: 8 REF_ECU
 SG_ S_EXT_0x195_S8_2 : 56|8@1- (1,0) [0|0] "" Vector__XXX
 SG_ S_EXT_0x195_S8_1 : 48|8@1- (1,0) [0|0] "" Vector__XXX
 SG_ S_EXT_0x195_S32_1 : 0|32@1- (1,0) [0|0] "" Vector__XXX
 SG_ S_EXT_0x195_S16_1 : 32|16@1- (1,0) [0|0] "" Vector__XXX

BO_ 2147484052 F_EXT_0x194: 8 REF_ECU
 SG_ S_EXT_0x194_S8_2 : 56|8@1- (1,0) [0|0] "" Vector__XXX
 SG_ S_EXT_0x194_S8_1 : 48|8@1- (1,0) [0|0] "" Vector__XXX
 SG_ S_EXT_0x194_S32_1 : 0|32@1- (1,0) [0|0] "" Vector__XXX
 SG_ S_EXT_0x194_S16_1 : 32|16@1- (1,0) [0|0] "" Vector__XXX

BO_ 2147484051 F_EXT_0x193: 8 REF_ECU
 SG_ S_EXT_0x193_S8_2 : 56|8@1- (1,0) [0|0] "" Vector__XXX
 SG_ S_EXT_0x193_S8_1 : 48|8@1- (1,0) [0|0] "" Vector__XXX
 SG_ S_EXT_0x193_S32_1 : 0|32@1- (1,0) [0|0] "" Vector__XXX
 SG_ S_EXT_0x193_S16_1 : 32|16@1- (1,0) [0|0] "" Vector__XXX

BO_ 2147484050 F_EXT_0x192: 8 REF_ECU
 SG_ S_EXT_0x192_S8_2 : 56|8@1- (1,0) [0|0] "" Vector__XXX
 SG_ S_EXT_0x192_S8_1 : 48|8@1- (1,0) [0|0] "" Vector__XXX
 SG_ S_EXT_0x192_S32_1 : 0|32@1- (1,0) [0|0] "" Vector__XXX
 SG_ S_EXT_0x192_S16_1 : 32|16@1- (1,0) [0|0] "" Vector__XXX

BO_ 2147484049 F_EXT_0x191: 8 REF_ECU
 SG_ S_EXT_0x191_S8_2 : 56|8@1- (1,0) [0|0] "" Vector__XXX
 SG_ S_EXT_0x191_S8_1 : 48|8@1- (1,0) [0|0] "" Vector__XXX
 SG_ S_EXT_0x191_S32_1 : 0|32@1- (1,0) [0|0] "" Vector__XXX
 SG_ S_EXT_0x191_S16_1 : 32|16@1- (1,0) [0|0] "" Vector__XXX

BO_ 2147484048 F_EXT_0x190: 8 REF_ECU
 SG_ S_EXT_0x190_S8_2 : 56|8@1- (1,0) [0|0] "" Vector__XXX
 SG_ S_EXT_0x190_S8_1 : 48|8@1- (1,0) [0|0] "" Vector__XXX
 SG_ S_EXT_0x190_S32_1 : 0|32@1- (1,0) [0|0] "" Vector__XXX
 SG_ S_EXT_0x190_S16_1 : 32|16@1- (1,0) [0|0] "" Vector__XXX

BO_ 2147484047 F_EXT_0x18F: 8 REF_ECU
 SG_ S_EXT_0x18F_S8_2 : 56|8@1- (1,0) [0|0] "" Vector__XXX
 SG_ S_EXT_0x18F_S8_1 : 48|8@1- (1,0) [0|0] "" Vector__XXX
 SG_ S_EXT_0x18F_S32_1 : 0|32@1- (1,0) [0|0] "" Vector__XXX
 SG_ S_EXT_0x18F_S16_1 : 32|16@1- (1,0) [0|0] "" Vector__XXX

BO_ 2147484046 F_EXT_0x18E: 8 REF_ECU
 SG_ S_EXT_0x18E_S8_2 : 56|8@1- (1,0) [0|0] "" Vector__XXX
 SG_ S_EXT_0x18E_S8_1 : 48|8@1- (1,0) [0|0] "" Vector__XXX
 SG_ S_EXT_0x18E_S32_1 : 0|32@1- (1,0) [0|0] "" Vector__XXX
 SG_ S_EXT_0x18E_S16_1 : 32|16@1- (1,0) [0|0] "" Vector__XXX

BO_ 2147484045 F_EXT_0x18D: 8 REF_ECU
 SG_ S_EXT_0x18D_S8_2 : 56|8@1- (1,0) [0|0] "" Vector__XXX
 SG_ S_EXT_0x18D_S8_1 : 48|8@1- (1,0) [0|0] "" Vector__XXX
 SG_ S_EXT_0x18D_S32_1 : 0|32@1- (1,0) [0|0] "" Vector__XXX
 SG_ S_EXT_0x18D_S16_1 : 32|16@1- (1,0) [0|0] "" Vector__XXX

BO_ 2147484044 F_EXT_0x18C: 8 REF_ECU
 SG_ S_EXT_0x18C_S8_2 : 56|8@1- (1,0) [0|0] "" Vector__XXX
 SG_ S_EXT_0x18C_S8_1 : 48|8@1- (1,0) [0|0] "" Vector__XXX
 SG_ S_EXT_0x18C_S32_1 : 0|32@1- (1,0) [0|0] "" Vector__XXX
 SG_ S_EXT_0x18C_S16_1 : 32|16@1- (1,0) [0|0] "" Vector__XXX

BO_ 2147484043 F_EXT_0x18B: 8 REF_ECU
 SG_ S_EXT_0x18B_S8_2 : 56|8@1- (1,0) [0|0] "" Vector__XXX
 SG_ S_EXT_0x18B_S8_1 : 48|8@1- (1,0) [0|0] "" Vector__XXX
 SG_ S_EXT_0x18B_S32_1 : 0|32@1- (1,0) [0|0] "" Vector__XXX
 SG_ S_EXT_0x18B_S16_1 : 32|16@1- (1,0) [0|0] "" Vector__XXX

BO_ 2147484042 F_EXT_0x18A: 8 REF_ECU
 SG_ S_EXT_0x18A_S8_2 : 56|8@1- (1,0) [0|0] "" Vector__XXX
 SG_ S_EXT_0x18A_S8_1 : 48|8@1- (1,0) [0|0] "" Vector__XXX
 SG_ S_EXT_0x18A_S32_1 : 0|32@1- (1,0) [0|0] "" Vector__XXX
 SG_ S_EXT_0x18A_S16_1 : 32|16@1- (1,0) [0|0] "" Vector__XXX

BO_ 2147484041 F_EXT_0x189: 8 REF_ECU
 SG_ S_EXT_0x189_S8_2 : 56|8@1- (1,0) [0|0] "" Vector__XXX
 SG_ S_EXT_0x189_S8_1 : 48|8@1- (1,0) [0|0] "" Vector__XXX
 SG_ S_EXT_0x189_S32_1 : 0|32@1- (1,0) [0|0] "" Vector__XXX
 SG_ S_EXT_0x189_S16_1 : 32|16@1- (1,0) [0|0] "" Vector__XXX

BO_ 2147484040 F_EXT_0x188: 8 REF_ECU
 SG_ S_EXT_0x188_S8_2 : 56|8@1- (1,0) [0|0] "" Vector__XXX
 SG_ S_EXT_0x188_S8_1 : 48|8@1- (1,0) [0|0] "" Vector__XXX
 SG_ S_EXT_0x188_S32_1 : 0|32@1- (1,0) [0|0] "" Vector__XXX
 SG_ S_EXT_0x188_S16_1 : 32|16@1- (1,0) [0|0] "" Vector__XXX

BO_ 2147484039 F_EXT_0x187: 8 REF_ECU
 SG_ S_EXT_0x187_S8_2 : 56|8@1- (1,0) [0|0] "" Vector__XXX
 SG_ S_EXT_0x187_S8_1 : 48|8@1- (1,0) [0|0] "" Vector__XXX
 SG_ S_EXT_0x187_S32_1 : 0|32@1- (1,0) [0|0] "" Vector__XXX
 SG_ S_EXT_0x187_S16_1 : 32|16@1- (1,0) [0|0] "" Vector__XXX

BO_ 2147484038 F_EXT_0x186: 8 REF_ECU
 SG_ S_EXT_0x186_S8_2 : 56|8@1- (1,0) [0|0] "" Vector__XXX
 SG_ S_EXT_0x186_S8_1 : 48|8@1- (1,0) [0|0] "" Vector__XXX
 SG_ S_EXT_0x186_S32_1 : 0|32@1- (1,0) [0|0] "" Vector__XXX
 SG_ S_EXT_0x186_S16_1 : 32|16@1- (1,0) [0|0] "" Vector__XXX

BO_ 2147484037 F_EXT_0x185: 8 REF_ECU
 SG_ S_EXT_0x185_S8_2 : 56|8@1- (1,0) [0|0] "" Vector__XXX
 SG_ S_EXT_0x185_S8_1 : 48|8@1- (1,0) [0|0] "" Vector__XXX
 SG_ S_EXT_0x185_S32_1 : 0|32@1- (1,0) [0|0] "" Vector__XXX
 SG_ S_EXT_0x185_S16_1 : 32|16@1- (1,0) [0|0] "" Vector__XXX

BO_ 2147484036 F_EXT_0x184: 8 REF_ECU
 SG_ S_EXT_0x184_S8_2 : 56|8@1- (1,0) [0|0] "" Vector__XXX
 SG_ S_EXT_0x184_S8_1 : 48|8@1- (1,0) [0|0] "" Vector__XXX
 SG_ S_EXT_0x184_S32_1 : 0|32@1- (1,0) [0|0] "" Vector__XXX
 SG_ S_EXT_0x184_S16_1 : 32|16@1- (1,0) [0|0] "" Vector__XXX

BO_ 2147484035 F_EXT_0x183: 8 REF_ECU
 SG_ S_EXT_0x183_S8_2 : 56|8@1- (1,0) [0|0] "" Vector__XXX
 SG_ S_EXT_0x183_S8_1 : 48|8@1- (1,0) [0|0] "" Vector__XXX
 SG_ S_EXT_0x183_S32_1 : 0|32@1- (1,0) [0|0] "" Vector__XXX
 SG_ S_EXT_0x183_S16_1 : 32|16@1- (1,0) [0|0] "" Vector__XXX

BO_ 2147484034 F_EXT_0x182: 8 REF_ECU
 SG_ S_EXT_0x182_S8_2 : 56|8@1- (1,0) [0|0] "" Vector__XXX
 SG_ S_EXT_0x182_S8_1 : 48|8@1- (1,0) [0|0] "" Vector__XXX
 SG_ S_EXT_0x182_S32_1 : 0|32@1- (1,0) [0|0] "" Vector__XXX
 SG_ S_EXT_0x182_S16_1 : 32|16@1- (1,0) [0|0] "" Vector__XXX

BO_ 2147484033 F_EXT_0x181: 8 REF_ECU
 SG_ S_EXT_0x181_S8_2 : 56|8@1- (1,0) [0|0] "" Vector__XXX
 SG_ S_EXT_0x181_S8_1 : 48|8@1- (1,0) [0|0] "" Vector__XXX
 SG_ S_EXT_0x181_S32_1 : 0|32@1- (1,0) [0|0] "" Vector__XXX
 SG_ S_EXT_0x181_S16_1 : 32|16@1- (1,0) [0|0] "" Vector__XXX

BO_ 2147484032 F_EXT_0x180: 8 REF_ECU
 SG_ S_EXT_0x180_S8_2 : 56|8@1- (1,0) [0|0] "" Vector__XXX
 SG_ S_EXT_0x180_S8_1 : 48|8@1- (1,0) [0|0] "" Vector__XXX
 SG_ S_EXT_0x180_S32_1 : 0|32@1- (1,0) [0|0] "" Vector__XXX
 SG_ S_EXT_0x180_S16_1 : 32|16@1- (1,0) [0|0] "" Vector__XXX

BO_ 2147484031 F_EXT_0x17F: 8 REF_ECU
 SG_ S_EXT_0x17F_S8_2 : 56|8@1- (1,0) [0|0] "" Vector__XXX
 SG_ S_EXT_0x17F_S8_1 : 48|8@1- (1,0) [0|0] "" Vector__XXX
 SG_ S_EXT_0x17F_S32_1 : 0|32@1- (1,0) [0|0] "" Vector__XXX
 SG_ S_EXT_0x17F_S16_1 : 32|16@1- (1,0) [0|0] "" Vector__XXX

BO_ 2147484030 F_EXT_0x17E: 8 REF_ECU
 SG_ S_EXT_0x17E_S8_2 : 56|8@1- (1,0) [0|0] "" Vector__XXX
 SG_ S_EXT_0x17E_S8_1 : 48|8@1- (1,0) [0|0] "" Vector__XXX
 SG_ S_EXT_0x17E_S32_1 : 0|32@1- (1,0) [0|0] "" Vector__XXX
 SG_ S_EXT_0x17E_S16_1 : 32|16@1- (1,0) [0|0] "" Vector__XXX

BO_ 2147484029 F_EXT_0x17D: 8 REF_ECU
 SG_ S_EXT_0x17D_S8_2 : 56|8@1- (1,0) [0|0] "" Vector__XXX
 SG_ S_EXT_0x17D_S8_1 : 48|8@1- (1,0) [0|0] "" Vector__XXX
 SG_ S_EXT_0x17D_S32_1 : 0|32@1- (1,0) [0|0] "" Vector__XXX
 SG_ S_EXT_0x17D_S16_1 : 32|16@1- (1,0) [0|0] "" Vector__XXX

BO_ 2147484028 F_EXT_0x17C: 8 REF_ECU
 SG_ S_EXT_0x17C_S8_2 : 56|8@1- (1,0) [0|0] "" Vector__XXX
 SG_ S_EXT_0x17C_S8_1 : 48|8@1- (1,0) [0|0] "" Vector__XXX
 SG_ S_EXT_0x17C_S32_1 : 0|32@1- (1,0) [0|0] "" Vector__XXX
 SG_ S_EXT_0x17C_S16_1 : 32|16@1- (1,0) [0|0] "" Vector__XXX

BO_ 2147484027 F_EXT_0x17B: 8 REF_ECU
 SG_ S_EXT_0x17B_S8_2 : 56|8@1- (1,0) [0|0] "" Vector__XXX
 SG_ S_EXT_0x17B_S8_1 : 48|8@1- (1,0) [0|0] "" Vector__XXX
 SG_ S_EXT_0x17B_S32_1 : 0|32@1- (1,0) [0|0] "" Vector__XXX
 SG_ S_EXT_0x17B_S16_1 : 32|16@1- (1,0) [0|0] "" Vector__XXX

BO_ 2147484026 F_EXT_0x17A: 8 REF_ECU
 SG_ S_EXT_0x17A_S8_2 : 56|8@1- (1,0) [0|0] "" Vector__XXX
 SG_ S_EXT_0x17A_S8_1 : 48|8@1- (1,0) [0|0] "" Vector__XXX
 SG_ S_EXT_0x17A_S32_1 : 0|32@1- (1,0) [0|0] "" Vector__XXX
 SG_ S_EXT_0x17A_S16_1 : 32|16@1- (1,0) [0|0] "" Vector__XXX

BO_ 2147484025 F_EXT_0x179: 8 REF_ECU
 SG_ S_EXT_0x179_S8_2 : 56|8@1- (1,0) [0|0] "" Vector__XXX
 SG_ S_EXT_0x179_S8_1 : 48|8@1- (1,0) [0|0] "" Vector__XXX
 SG_ S_EXT_0x179_S32_1 : 0|32@1- (1,0) [0|0] "" Vector__XXX
 SG_ S_EXT_0x179_S16_1 : 32|16@1- (1,0) [0|0] "" Vector__XXX

BO_ 2147484024 F_EXT_0x178: 8 REF_ECU
 SG_ S_EXT_0x178_S8_2 : 56|8@1- (1,0) [0|0] "" Vector__XXX
 SG_ S_EXT_0x178_S8_1 : 48|8@1- (1,0) [0|0] "" Vector__XXX
 SG_ S_EXT_0x178_S32_1 : 0|32@1- (1,0) [0|0] "" Vector__XXX
 SG_ S_EXT_0x178_S16_1 : 32|16@1- (1,0) [0|0] "" Vector__XXX

BO_ 2147484023 F_EXT_0x177: 8 REF_ECU
 SG_ S_EXT_0x177_S8_2 : 56|8@1- (1,0) [0|0] "" Vector__XXX
 SG_ S_EXT_0x177_S8_1 : 48|8@1- (1,0) [0|0] "" Vector__XXX
 SG_ S_EXT_0x177_S32_1 : 0|32@1- (1,0) [0|0] "" Vector__XXX
 SG_ S_EXT_0x177_S16_1 : 32|16@1- (1,0) [0|0] "" Vector__XXX

BO_ 2147484022 F_EXT_0x176: 8 REF_ECU
 SG_ S_EXT_0x176_S8_2 : 56|8@1- (1,0) [0|0] "" Vector__XXX
 SG_ S_EXT_0x176_S8_1 : 48|8@1- (1,0) [0|0] "" Vector__XXX
 SG_ S_EXT_0x176_S32_1 : 0|32@1- (1,0) [0|0] "" Vector__XXX
 SG_ S_EXT_0x176_S16_1 : 32|16@1- (1,0) [0|0] "" Vector__XXX

BO_ 2147484021 F_EXT_0x175: 8 REF_ECU
 SG_ S_EXT_0x175_S8_2 : 56|8@1- (1,0) [0|0] "" Vector__XXX
 SG_ S_EXT_0x175_S8_1 : 48|8@1- (1,0) [0|0] "" Vector__XXX
 SG_ S_EXT_0x175_S32_1 : 0|32@1- (1,0) [0|0] "" Vector__XXX
 SG_ S_EXT_0x175_S16_1 : 32|16@1- (1,0) [0|0] "" Vector__XXX

BO_ 2147484020 F_EXT_0x174: 8 REF_ECU
 SG_ S_EXT_0x174_S8_2 : 56|8@1- (1,0) [0|0] "" Vector__XXX
 SG_ S_EXT_0x174_S8_1 : 48|8@1- (1,0) [0|0] "" Vector__XXX
 SG_ S_EXT_0x174_S32_1 : 0|32@1- (1,0) [0|0] "" Vector__XXX
 SG_ S_EXT_0x174_S16_1 : 32|16@1- (1,0) [0|0] "" Vector__XXX

BO_ 2147484019 F_EXT_0x173: 8 REF_ECU
 SG_ S_EXT_0x173_S8_2 : 56|8@1- (1,0) [0|0] "" Vector__XXX
 SG_ S_EXT_0x173_S8_1 : 48|8@1- (1,0) [0|0] "" Vector__XXX
 SG_ S_EXT_0x173_S32_1 : 0|32@1- (1,0) [0|0] "" Vector__XXX
 SG_ S_EXT_0x173_S16_1 : 32|16@1- (1,0) [0|0] "" Vector__XXX

BO_ 2147484018 F_EXT_0x172: 8 REF_ECU
 SG_ S_EXT_0x172_S8_2 : 56|8@1- (1,0) [0|0] "" Vector__XXX
 SG_ S_EXT_0x172_S8_1 : 48|8@1- (1,0) [0|0] "" Vector__XXX
 SG_ S_EXT_0x172_S32_1 : 0|32@1- (1,0) [0|0] "" Vector__XXX
 SG_ S_EXT_0x172_S16_1 : 32|16@1- (1,0) [0|0] "" Vector__XXX

BO_ 2147484017 F_EXT_0x171: 8 REF_ECU
 SG_ S_EXT_0x171_S8_2 : 56|8@1- (1,0) [0|0] "" Vector__XXX
 SG_ S_EXT_0x171_S8_1 : 48|8@1- (1,0) [0|0] "" Vector__XXX
 SG_ S_EXT_0x171_S32_1 : 0|32@1- (1,0) [0|0] "" Vector__XXX
 SG_ S_EXT_0x171_S16_1 : 32|16@1- (1,0) [0|0] "" Vector__XXX

BO_ 2147484016 F_EXT_0x170: 8 REF_ECU
 SG_ S_EXT_0x170_S8_2 : 56|8@1- (1,0) [0|0] "" Vector__XXX
 SG_ S_EXT_0x170_S8_1 : 48|8@1- (1,0) [0|0] "" Vector__XXX
 SG_ S_EXT_0x170_S32_1 : 0|32@1- (1,0) [0|0] "" Vector__XXX
 SG_ S_EXT_0x170_S16_1 : 32|16@1- (1,0) [0|0] "" Vector__XXX

BO_ 2147484015 F_EXT_0x16F: 8 REF_ECU
 SG_ S_EXT_0x16F_S8_2 : 56|8@1- (1,0) [0|0] "" Vector__XXX
 SG_ S_EXT_0x16F_S8_1 : 48|8@1- (1,0) [0|0] "" Vector__XXX
 SG_ S_EXT_0x16F_S32_1 : 0|32@1- (1,0) [0|0] "" Vector__XXX
 SG_ S_EXT_0x16F_S16_1 : 32|16@1- (1,0) [0|0] "" Vector__XXX

BO_ 2147484014 F_EXT_0x16E: 8 REF_ECU
 SG_ S_EXT_0x16E_S8_2 : 56|8@1- (1,0) [0|0] "" Vector__XXX
 SG_ S_EXT_0x16E_S8_1 : 48|8@1- (1,0) [0|0] "" Vector__XXX
 SG_ S_EXT_0x16E_S32_1 : 0|32@1- (1,0) [0|0] "" Vector__XXX
 SG_ S_EXT_0x16E_S16_1 : 32|16@1- (1,0) [0|0] "" Vector__XXX

BO_ 2147484013 F_EXT_0x16D: 8 REF_ECU
 SG_ S_EXT_0x16D_S8_2 : 56|8@1- (1,0) [0|0] "" Vector__XXX
 SG_ S_EXT_0x16D_S8_1 : 48|8@1- (1,0) [0|0] "" Vector__XXX
 SG_ S_EXT_0x16D_S32_1 : 0|32@1- (1,0) [0|0] "" Vector__XXX
 SG_ S_EXT_0x16D_S16_1 : 32|16@1- (1,0) [0|0] "" Vector__XXX

BO_ 2147484012 F_EXT_0x16C: 8 REF_ECU
 SG_ S_EXT_0x16C_S8_2 : 56|8@1- (1,0) [0|0] "" Vector__XXX
 SG_ S_EXT_0x16C_S8_1 : 48|8@1- (1,0) [0|0] "" Vector__XXX
 SG_ S_EXT_0x16C_S32_1 : 0|32@1- (1,0) [0|0] "" Vector__XXX
 SG_ S_EXT_0x16C_S16_1 : 32|16@1- (1,0) [0|0] "" Vector__XXX

BO_ 2147484011 F_EXT_0x16B: 8 REF_ECU
 SG_ S_EXT_0x16B_S8_2 : 56|8@1- (1,0) [0|0] "" Vector__XXX
 SG_ S_EXT_0x16B_S8_1 : 48|8@1- (1,0) [0|0] "" Vector__XXX
 SG_ S_EXT_0x16B_S32_1 : 0|32@1- (1,0) [0|0] "" Vector__XXX
 SG_ S_EXT_0x16B_S16_1 : 32|16@1- (1,0) [0|0] "" Vector__XXX

BO_ 2147484010 F_EXT_0x16A: 8 REF_ECU
 SG_ S_EXT_0x16A_S8_2 : 56|8@1- (1,0) [0|0] "" Vector__XXX
 SG_ S_EXT_0x16A_S8_1 : 48|8@1- (1,0) [0|0] "" Vector__XXX
 SG_ S_EXT_0x16A_S32_1 : 0|32@1- (1,0) [0|0] "" Vector__XXX
 SG_ S_EXT_0x16A_S16_1 : 32|16@1- (1,0) [0|0] "" Vector__XXX

BO_ 2147484009 F_EXT_0x169: 8 REF_ECU
 SG_ S_EXT_0x169_S8_2 : 56|8@1- (1,0) [0|0] "" Vector__XXX
 SG_ S_EXT_0x169_S8_1 : 48|8@1- (1,0) [0|0] "" Vector__XXX
 SG_ S_EXT_0x169_S32_1 : 0|32@1- (1,0) [0|0] "" Vector__XXX
 SG_ S_EXT_0x169_S16_1 : 32|16@1- (1,0) [0|0] "" Vector__XXX

BO_ 2147484008 F_EXT_0x168: 8 REF_ECU
 SG_ S_EXT_0x168_S8_2 : 56|8@1- (1,0) [0|0] "" Vector__XXX
 SG_ S_EXT_0x168_S8_1 : 48|8@1- (1,0) [0|0] "" Vector__XXX
 SG_ S_EXT_0x168_S32_1 : 0|32@1- (1,0) [0|0] "" Vector__XXX
 SG_ S_EXT_0x168_S16_1 : 32|16@1- (1,0) [0|0] "" Vector__XXX

BO_ 2147484007 F_EXT_0x167: 8 REF_ECU
 SG_ S_EXT_0x167_S8_2 : 56|8@1- (1,0) [0|0] "" Vector__XXX
 SG_ S_EXT_0x167_S8_1 : 48|8@1- (1,0) [0|0] "" Vector__XXX
 SG_ S_EXT_0x167_S32_1 : 0|32@1- (1,0) [0|0] "" Vector__XXX
 SG_ S_EXT_0x167_S16_1 : 32|16@1- (1,0) [0|0] "" Vector__XXX

BO_ 2147484006 F_EXT_0x166: 8 REF_ECU
 SG_ S_EXT_0x166_S8_2 : 56|8@1- (1,0) [0|0] "" Vector__XXX
 SG_ S_EXT_0x166_S8_1 : 48|8@1- (1,0) [0|0] "" Vector__XXX
 SG_ S_EXT_0x166_S32_1 : 0|32@1- (1,0) [0|0] "" Vector__XXX
 SG_ S_EXT_0x166_S16_1 : 32|16@1- (1,0) [0|0] "" Vector__XXX

BO_ 2147484005 F_EXT_0x165: 8 REF_ECU
 SG_ S_EXT_0x165_S8_2 : 56|8@1- (1,0) [0|0] "" Vector__XXX
 SG_ S_EXT_0x165_S8_1 : 48|8@1- (1,0) [0|0] "" Vector__XXX
 SG_ S_EXT_0x165_S32_1 : 0|32@1- (1,0) [0|0] "" Vector__XXX
 SG_ S_EXT_0x165_S16_1 : 32|16@1- (1,0) [0|0] "" Vector__XXX

BO_ 2147484004 F_EXT_0x164: 8 REF_ECU
 SG_ S_EXT_0x164_S8_2 : 56|8@1- (1,0) [0|0] "" Vector__XXX
 SG_ S_EXT_0x164_S8_1 : 48|8@1- (1,0) [0|0] "" Vector__XXX
 SG_ S_EXT_0x164_S32_1 : 0|32@1- (1,0) [0|0] "" Vector__XXX
 SG_ S_EXT_0x164_S16_1 : 32|16@1- (1,0) [0|0] "" Vector__XXX

BO_ 2147484003 F_EXT_0x163: 8 REF_ECU
 SG_ S_EXT_0x163_S8_2 : 56|8@1- (1,0) [0|0] "" Vector__XXX
 SG_ S_EXT_0x163_S8_1 : 48|8@1- (1,0) [0|0] "" Vector__XXX
 SG_ S_EXT_0x163_S32_1 : 0|32@1- (1,0) [0|0] "" Vector__XXX
 SG_ S_EXT_0x163_S16_1 : 32|16@1- (1,0) [0|0] "" Vector__XXX

BO_ 2147484002 F_EXT_0x162: 8 REF_ECU
 SG_ S_EXT_0x162_S8_2 : 56|8@1- (1,0) [0|0] "" Vector__XXX
 SG_ S_EXT_0x162_S8_1 : 48|8@1- (1,0) [0|0] "" Vector__XXX
 SG_ S_EXT_0x162_S32_1 : 0|32@1- (1,0) [0|0] "" Vector__XXX
 SG_ S_EXT_0x162_S16_1 : 32|16@1- (1,0) [0|0] "" Vector__XXX

BO_ 2147484001 F_EXT_0x161: 8 REF_ECU
 SG_ S_EXT_0x161_S8_2 : 56|8@1- (1,0) [0|0] "" Vector__XXX
 SG_ S_EXT_0x161_S8_1 : 48|8@1- (1,0) [0|0] "" Vector__XXX
 SG_ S_EXT_0x161_S32_1 : 0|32@1- (1,0) [0|0] "" Vector__XXX
 SG_ S_EXT_0x161_S16_1 : 32|16@1- (1,0) [0|0] "" Vector__XXX

BO_ 2147484000 F_EXT_0x160: 8 REF_ECU
 SG_ S_EXT_0x160_S8_2 : 56|8@1- (1,0) [0|0] "" Vector__XXX
 SG_ S_EXT_0x160_S8_1 : 48|8@1- (1,0) [0|0] "" Vector__XXX
 SG_ S_EXT_0x160_S32_1 : 0|32@1- (1,0) [0|0] "" Vector__XXX
 SG_ S_EXT_0x160_S16_1 : 32|16@1- (1,0) [0|0] "" Vector__XXX

BO_ 2147483999 F_EXT_0x15F: 8 REF_ECU
 SG_ S_EXT_0x15F_S8_2 : 56|8@1- (1,0) [0|0] "" Vector__XXX
 SG_ S_EXT_0x15F_S8_1 : 48|8@1- (1,0) [0|0] "" Vector__XXX
 SG_ S_EXT_0x15F_S32_1 : 0|32@1- (1,0) [0|0] "" Vector__XXX
 SG_ S_EXT_0x15F_S16_1 : 32|16@1- (1,0) [0|0] "" Vector__XXX

BO_ 2147483998 F_EXT_0x15E: 8 REF_ECU
 SG_ S_EXT_0x15E_S8_2 : 56|8@1- (1,0) [0|0] "" Vector__XXX
 SG_ S_EXT_0x15E_S8_1 : 48|8@1- (1,0) [0|0] "" Vector__XXX
 SG_ S_EXT_0x15E_S32_1 : 0|32@1- (1,0) [0|0] "" Vector__XXX
 SG_ S_EXT_0x15E_S16_1 : 32|16@1- (1,0) [0|0] "" Vector__XXX

BO_ 2147483997 F_EXT_0x15D: 8 REF_ECU
 SG_ S_EXT_0x15D_S8_2 : 56|8@1- (1,0) [0|0] "" Vector__XXX
 SG_ S_EXT_0x15D_S8_1 : 48|8@1- (1,0) [0|0] "" Vector__XXX
 SG_ S_EXT_0x15D_S32_1 : 0|32@1- (1,0) [0|0] "" Vector__XXX
 SG_ S_EXT_0x15D_S16_1 : 32|16@1- (1,0) [0|0] "" Vector__XXX

BO_ 2147483996 F_EXT_0x15C: 8 REF_ECU
 SG_ S_EXT_0x15C_S8_2 : 56|8@1- (1,0) [0|0] "" Vector__XXX
 SG_ S_EXT_0x15C_S8_1 : 48|8@1- (1,0) [0|0] "" Vector__XXX
 SG_ S_EXT_0x15C_S32_1 : 0|32@1- (1,0) [0|0] "" Vector__XXX
 SG_ S_EXT_0x15C_S16_1 : 32|16@1- (1,0) [0|0] "" Vector__XXX

BO_ 2147483995 F_EXT_0x15B: 8 REF_ECU
 SG_ S_EXT_0x15B_S8_2 : 56|8@1- (1,0) [0|0] "" Vector__XXX
 SG_ S_EXT_0x15B_S8_1 : 48|8@1- (1,0) [0|0] "" Vector__XXX
 SG_ S_EXT_0x15B_S32_1 : 0|32@1- (1,0) [0|0] "" Vector__XXX
 SG_ S_EXT_0x15B_S16_1 : 32|16@1- (1,0) [0|0] "" Vector__XXX

BO_ 2147483994 F_EXT_0x15A: 8 REF_ECU
 SG_ S_EXT_0x15A_S8_2 : 56|8@1- (1,0) [0|0] "" Vector__XXX
 SG_ S_EXT_0x15A_S8_1 : 48|8@1- (1,0) [0|0] "" Vector__XXX
 SG_ S_EXT_0x15A_S32_1 : 0|32@1- (1,0) [0|0] "" Vector__XXX
 SG_ S_EXT_0x15A_S16_1 : 32|16@1- (1,0) [0|0] "" Vector__XXX

BO_ 2147483993 F_EXT_0x159: 8 REF_ECU
 SG_ S_EXT_0x159_S8_2 : 56|8@1- (1,0) [0|0] "" Vector__XXX
 SG_ S_EXT_0x159_S8_1 : 48|8@1- (1,0) [0|0] "" Vector__XXX
 SG_ S_EXT_0x159_S32_1 : 0|32@1- (1,0) [0|0] "" Vector__XXX
 SG_ S_EXT_0x159_S16_1 : 32|16@1- (1,0) [0|0] "" Vector__XXX

BO_ 2147483992 F_EXT_0x158: 8 REF_ECU
 SG_ S_EXT_0x158_S8_2 : 56|8@1- (1,0) [0|0] "" Vector__XXX
 SG_ S_EXT_0x158_S8_1 : 48|8@1- (1,0) [0|0] "" Vector__XXX
 SG_ S_EXT_0x158_S32_1 : 0|32@1- (1,0) [0|0] "" Vector__XXX
 SG_ S_EXT_0x158_S16_1 : 32|16@1- (1,0) [0|0] "" Vector__XXX

BO_ 2147483991 F_EXT_0x157: 8 REF_ECU
 SG_ S_EXT_0x157_S8_2 : 56|8@1- (1,0) [0|0] "" Vector__XXX
 SG_ S_EXT_0x157_S8_1 : 48|8@1- (1,0) [0|0] "" Vector__XXX
 SG_ S_EXT_0x157_S32_1 : 0|32@1- (1,0) [0|0] "" Vector__XXX
 SG_ S_EXT_0x157_S16_1 : 32|16@1- (1,0) [0|0] "" Vector__XXX

BO_ 2147483990 F_EXT_0x156: 8 REF_ECU
 SG_ S_EXT_0x156_S8_2 : 56|8@1- (1,0) [0|0] "" Vector__XXX
 SG_ S_EXT_0x156_S8_1 : 48|8@1- (1,0) [0|0] "" Vector__XXX
 SG_ S_EXT_0x156_S32_1 : 0|32@1- (1,0) [0|0] "" Vector__XXX
 SG_ S_EXT_0x156_S16_1 : 32|16@1- (1,0) [0|0] "" Vector__XXX

BO_ 2147483989 F_EXT_0x155: 8 REF_ECU
 SG_ S_EXT_0x155_S8_2 : 56|8@1- (1,0) [0|0] "" Vector__XXX
 SG_ S_EXT_0x155_S8_1 : 48|8@1- (1,0) [0|0] "" Vector__XXX
 SG_ S_EXT_0x155_S32_1 : 0|32@1- (1,0) [0|0] "" Vector__XXX
 SG_ S_EXT_0x155_S16_1 : 32|16@1- (1,0) [0|0] "" Vector__XXX

BO_ 2147483988 F_EXT_0x154: 8 REF_ECU
 SG_ S_EXT_0x154_S8_2 : 56|8@1- (1,0) [0|0] "" Vector__XXX
 SG_ S_EXT_0x154_S8_1 : 48|8@1- (1,0) [0|0] "" Vector__XXX
 SG_ S_EXT_0x154_S32_1 : 0|32@1- (1,0) [0|0] "" Vector__XXX
 SG_ S_EXT_0x154_S16_1 : 32|16@1- (1,0) [0|0] "" Vector__XXX

BO_ 2147483987 F_EXT_0x153: 8 REF_ECU
 SG_ S_EXT_0x153_S8_2 : 56|8@1- (1,0) [0|0] "" Vector__XXX
 SG_ S_EXT_0x153_S8_1 : 48|8@1- (1,0) [0|0] "" Vector__XXX
 SG_ S_EXT_0x153_S32_1 : 0|32@1- (1,0) [0|0] "" Vector__XXX
 SG_ S_EXT_0x153_S16_1 : 32|16@1- (1,0) [0|0] "" Vector__XXX

BO_ 2147483986 F_EXT_0x152: 8 REF_ECU
 SG_ S_EXT_0x152_S8_2 : 56|8@1- (1,0) [0|0] "" Vector__XXX
 SG_ S_EXT_0x152_S8_1 : 48|8@1- (1,0) [0|0] "" Vector__XXX
 SG_ S_EXT_0x152_S32_1 : 0|32@1- (1,0) [0|0] "" Vector__XXX
 SG_ S_EXT_0x152_S16_1 : 32|16@1- (1,0) [0|0] "" Vector__XXX

BO_ 2147483985 F_EXT_0x151: 8 REF_ECU
 SG_ S_EXT_0x151_S8_2 : 56|8@1- (1,0) [0|0] "" Vector__XXX
 SG_ S_EXT_0x151_S8_1 : 48|8@1- (1,0) [0|0] "" Vector__XXX
 SG_ S_EXT_0x151_S32_1 : 0|32@1- (1,0) [0|0] "" Vector__XXX
 SG_ S_EXT_0x151_S16_1 : 32|16@1- (1,0) [0|0] "" Vector__XXX

BO_ 2147483984 F_EXT_0x150: 8 REF_ECU
 SG_ S_EXT_0x150_S8_2 : 56|8@1- (1,0) [0|0] "" Vector__XXX
 SG_ S_EXT_0x150_S8_1 : 48|8@1- (1,0) [0|0] "" Vector__XXX
 SG_ S_EXT_0x150_S32_1 : 0|32@1- (1,0) [0|0] "" Vector__XXX
 SG_ S_EXT_0x150_S16_1 : 32|16@1- (1,0) [0|0] "" Vector__XXX

BO_ 335 F_STD_0x14F: 8 REF_ECU
 SG_ S_STD_0x14F_S8_2 : 56|8@1- (1,0) [0|0] "" Vector__XXX
 SG_ S_STD_0x14F_S8_1 : 48|8@1- (1,0) [0|0] "" Vector__XXX
 SG_ S_STD_0x14F_S32_1 : 0|32@1- (1,0) [0|0] "" Vector__XXX
 SG_ S_STD_0x14F_S16_1 : 32|16@1- (1,0) [0|0] "" Vector__XXX

BO_ 334 F_STD_0x14E: 8 REF_ECU
 SG_ S_STD_0x14E_S8_2 : 56|8@1- (1,0) [0|0] "" Vector__XXX
 SG_ S_STD_0x14E_S8_1 : 48|8@1- (1,0) [0|0] "" Vector__XXX
 SG_ S_STD_0x14E_S32_1 : 0|32@1- (1,0) [0|0] "" Vector__XXX
 SG_ S_STD_0x14E_S16_1 : 32|16@1- (1,0) [0|0] "" Vector__XXX

BO_ 333 F_STD_0x14D: 8 REF_ECU
 SG_ S_STD_0x14D_S8_2 : 56|8@1- (1,0) [0|0] "" Vector__XXX
 SG_ S_STD_0x14D_S8_1 : 48|8@1- (1,0) [0|0] "" Vector__XXX
 SG_ S_STD_0x14D_S32_1 : 0|32@1- (1,0) [0|0] "" Vector__XXX
 SG_ S_STD_0x14D_S16_1 : 32|16@1- (1,0) [0|0] "" Vector__XXX

BO_ 332 F_STD_0x14C: 8 REF_ECU
 SG_ S_STD_0x14C_S8_2 : 56|8@1- (1,0) [0|0] "" Vector__XXX
 SG_ S_STD_0x14C_S8_1 : 48|8@1- (1,0) [0|0] "" Vector__XXX
 SG_ S_STD_0x14C_S32_1 : 0|32@1- (1,0) [0|0] "" Vector__XXX
 SG_ S_STD_0x14C_S16_1 : 32|16@1- (1,0) [0|0] "" Vector__XXX

BO_ 331 F_STD_0x14B: 8 REF_ECU
 SG_ S_STD_0x14B_S8_2 : 56|8@1- (1,0) [0|0] "" Vector__XXX
 SG_ S_STD_0x14B_S8_1 : 48|8@1- (1,0) [0|0] "" Vector__XXX
 SG_ S_STD_0x14B_S32_1 : 0|32@1- (1,0) [0|0] "" Vector__XXX
 SG_ S_STD_0x14B_S16_1 : 32|16@1- (1,0) [0|0] "" Vector__XXX

BO_ 330 F_STD_0x14A: 8 REF_ECU
 SG_ S_STD_0x14A_S8_2 : 56|8@1- (1,0) [0|0] "" Vector__XXX
 SG_ S_STD_0x14A_S8_1 : 48|8@1- (1,0) [0|0] "" Vector__XXX
 SG_ S_STD_0x14A_S32_1 : 0|32@1- (1,0) [0|0] "" Vector__XXX
 SG_ S_STD_0x14A_S16_1 : 32|16@1- (1,0) [0|0] "" Vector__XXX

BO_ 329 F_STD_0x149: 8 REF_ECU
 SG_ S_STD_0x149_S8_2 : 56|8@1- (1,0) [0|0] "" Vector__XXX
 SG_ S_STD_0x149_S8_1 : 48|8@1- (1,0) [0|0] "" Vector__XXX
 SG_ S_STD_0x149_S32_1 : 0|32@1- (1,0) [0|0] "" Vector__XXX
 SG_ S_STD_0x149_S16_1 : 32|16@1- (1,0) [0|0] "" Vector__XXX

BO_ 328 F_STD_0x148: 8 REF_ECU
 SG_ S_STD_0x148_S8_2 : 56|8@1- (1,0) [0|0] "" Vector__XXX
 SG_ S_STD_0x148_S8_1 : 48|8@1- (1,0) [0|0] "" Vector__XXX
 SG_ S_STD_0x148_S32_1 : 0|32@1- (1,0) [0|0] "" Vector__XXX
 SG_ S_STD_0x148_S16_1 : 32|16@1- (1,0) [0|0] "" Vector__XXX

BO_ 327 F_STD_0x147: 8 REF_ECU
 SG_ S_STD_0x147_S8_2 : 56|8@1- (1,0) [0|0] "" Vector__XXX
 SG_ S_STD_0x147_S8_1 : 48|8@1- (1,0) [0|0] "" Vector__XXX
 SG_ S_STD_0x147_S32_1 : 0|32@1- (1,0) [0|0] "" Vector__XXX
 SG_ S_STD_0x147_S16_1 : 32|16@1- (1,0) [0|0] "" Vector__XXX

BO_ 326 F_STD_0x146: 8 REF_ECU
 SG_ S_STD_0x146_S8_2 : 56|8@1- (1,0) [0|0] "" Vector__XXX
 SG_ S_STD_0x146_S8_1 : 48|8@1- (1,0) [0|0] "" Vector__XXX
 SG_ S_STD_0x146_S32_1 : 0|32@1- (1,0) [0|0] "" Vector__XXX
 SG_ S_STD_0x146_S16_1 : 32|16@1- (1,0) [0|0] "" Vector__XXX

BO_ 325 F_STD_0x145: 8 REF_ECU
 SG_ S_STD_0x145_S8_2 : 56|8@1- (1,0) [0|0] "" Vector__XXX
 SG_ S_STD_0x145_S8_1 : 48|8@1- (1,0) [0|0] "" Vector__XXX
 SG_ S_STD_0x145_S32_1 : 0|32@1- (1,0) [0|0] "" Vector__XXX
 SG_ S_STD_0x145_S16_1 : 32|16@1- (1,0) [0|0] "" Vector__XXX

BO_ 324 F_STD_0x144: 8 REF_ECU
 SG_ S_STD_0x144_S8_2 : 56|8@1- (1,0) [0|0] "" Vector__XXX
 SG_ S_STD_0x144_S8_1 : 48|8@1- (1,0) [0|0] "" Vector__XXX
 SG_ S_STD_0x144_S32_1 : 0|32@1- (1,0) [0|0] "" Vector__XXX
 SG_ S_STD_0x144_S16_1 : 32|16@1- (1,0) [0|0] "" Vector__XXX

BO_ 323 F_STD_0x143: 8 REF_ECU
 SG_ S_STD_0x143_S8_2 : 56|8@1- (1,0) [0|0] "" Vector__XXX
 SG_ S_STD_0x143_S8_1 : 48|8@1- (1,0) [0|0] "" Vector__XXX
 SG_ S_STD_0x143_S32_1 : 0|32@1- (1,0) [0|0] "" Vector__XXX
 SG_ S_STD_0x143_S16_1 : 32|16@1- (1,0) [0|0] "" Vector__XXX

BO_ 322 F_STD_0x142: 8 REF_ECU
 SG_ S_STD_0x142_S8_2 : 56|8@1- (1,0) [0|0] "" Vector__XXX
 SG_ S_STD_0x142_S8_1 : 48|8@1- (1,0) [0|0] "" Vector__XXX
 SG_ S_STD_0x142_S32_1 : 0|32@1- (1,0) [0|0] "" Vector__XXX
 SG_ S_STD_0x142_S16_1 : 32|16@1- (1,0) [0|0] "" Vector__XXX

BO_ 321 F_STD_0x141: 8 REF_ECU
 SG_ S_STD_0x141_S8_2 : 56|8@1- (1,0) [0|0] "" Vector__XXX
 SG_ S_STD_0x141_S8_1 : 48|8@1- (1,0) [0|0] "" Vector__XXX
 SG_ S_STD_0x141_S32_1 : 0|32@1- (1,0) [0|0] "" Vector__XXX
 SG_ S_STD_0x141_S16_1 : 32|16@1- (1,0) [0|0] "" Vector__XXX

BO_ 320 F_STD_0x140: 8 REF_ECU
 SG_ S_STD_0x140_S8_2 : 56|8@1- (1,0) [0|0] "" Vector__XXX
 SG_ S_STD_0x140_S8_1 : 48|8@1- (1,0) [0|0] "" Vector__XXX
 SG_ S_STD_0x140_S32_1 : 0|32@1- (1,0) [0|0] "" Vector__XXX
 SG_ S_STD_0x140_S16_1 : 32|16@1- (1,0) [0|0] "" Vector__XXX

BO_ 319 F_STD_0x13F: 8 REF_ECU
 SG_ S_STD_0x13F_S8_2 : 56|8@1- (1,0) [0|0] "" Vector__XXX
 SG_ S_STD_0x13F_S8_1 : 48|8@1- (1,0) [0|0] "" Vector__XXX
 SG_ S_STD_0x13F_S32_1 : 0|32@1- (1,0) [0|0] "" Vector__XXX
 SG_ S_STD_0x13F_S16_1 : 32|16@1- (1,0) [0|0] "" Vector__XXX

BO_ 318 F_STD_0x13E: 8 REF_ECU
 SG_ S_STD_0x13E_S8_2 : 56|8@1- (1,0) [0|0] "" Vector__XXX
 SG_ S_STD_0x13E_S8_1 : 48|8@1- (1,0) [0|0] "" Vector__XXX
 SG_ S_STD_0x13E_S32_1 : 0|32@1- (1,0) [0|0] "" Vector__XXX
 SG_ S_STD_0x13E_S16_1 : 32|16@1- (1,0) [0|0] "" Vector__XXX

BO_ 317 F_STD_0x13D: 8 REF_ECU
 SG_ S_STD_0x13D_S8_2 : 56|8@1- (1,0) [0|0] "" Vector__XXX
 SG_ S_STD_0x13D_S8_1 : 48|8@1- (1,0) [0|0] "" Vector__XXX
 SG_ S_STD_0x13D_S32_1 : 0|32@1- (1,0) [0|0] "" Vector__XXX
 SG_ S_STD_0x13D_S16_1 : 32|16@1- (1,0) [0|0] "" Vector__XXX

BO_ 316 F_STD_0x13C: 8 REF_ECU
 SG_ S_STD_0x13C_S8_2 : 56|8@1- (1,0) [0|0] "" Vector__XXX
 SG_ S_STD_0x13C_S8_1 : 48|8@1- (1,0) [0|0] "" Vector__XXX
 SG_ S_STD_0x13C_S32_1 : 0|32@1- (1,0) [0|0] "" Vector__XXX
 SG_ S_STD_0x13C_S16_1 : 32|16@1- (1,0) [0|0] "" Vector__XXX

BO_ 315 F_STD_0x13B: 8 REF_ECU
 SG_ S_STD_0x13B_S8_2 : 56|8@1- (1,0) [0|0] "" Vector__XXX
 SG_ S_STD_0x13B_S8_1 : 48|8@1- (1,0) [0|0] "" Vector__XXX
 SG_ S_STD_0x13B_S32_1 : 0|32@1- (1,0) [0|0] "" Vector__XXX
 SG_ S_STD_0x13B_S16_1 : 32|16@1- (1,0) [0|0] "" Vector__XXX

BO_ 314 F_STD_0x13A: 8 REF_ECU
 SG_ S_STD_0x13A_S8_2 : 56|8@1- (1,0) [0|0] "" Vector__XXX
 SG_ S_STD_0x13A_S8_1 : 48|8@1- (1,0) [0|0] "" Vector__XXX
 SG_ S_STD_0x13A_S32_1 : 0|32@1- (1,0) [0|0] "" Vector__XXX
 SG_ S_STD_0x13A_S16_1 : 32|16@1- (1,0) [0|0] "" Vector__XXX

BO_ 313 F_STD_0x139: 8 REF_ECU
 SG_ S_STD_0x139_S8_2 : 56|8@1- (1,0) [0|0] "" Vector__XXX
 SG_ S_STD_0x139_S8_1 : 48|8@1- (1,0) [0|0] "" Vector__XXX
 SG_ S_STD_0x139_S32_1 : 0|32@1- (1,0) [0|0] "" Vector__XXX
 SG_ S_STD_0x139_S16_1 : 32|16@1- (1,0) [0|0] "" Vector__XXX

BO_ 312 F_STD_0x138: 8 REF_ECU
 SG_ S_STD_0x138_S8_2 : 56|8@1- (1,0) [0|0] "" Vector__XXX
 SG_ S_STD_0x138_S8_1 : 48|8@1- (1,0) [0|0] "" Vector__XXX
 SG_ S_STD_0x138_S32_1 : 0|32@1- (1,0) [0|0] "" Vector__XXX
 SG_ S_STD_0x138_S16_1 : 32|16@1- (1,0) [0|0] "" Vector__XXX

BO_ 311 F_STD_0x137: 8 REF_ECU
 SG_ S_STD_0x137_S8_2 : 56|8@1- (1,0) [0|0] "" Vector__XXX
 SG_ S_STD_0x137_S8_1 : 48|8@1- (1,0) [0|0] "" Vector__XXX
 SG_ S_STD_0x137_S32_1 : 0|32@1- (1,0) [0|0] "" Vector__XXX
 SG_ S_STD_0x137_S16_1 : 32|16@1- (1,0) [0|0] "" Vector__XXX

BO_ 310 F_STD_0x136: 8 REF_ECU
 SG_ S_STD_0x136_S8_2 : 56|8@1- (1,0) [0|0] "" Vector__XXX
 SG_ S_STD_0x136_S8_1 : 48|8@1- (1,0) [0|0] "" Vector__XXX
 SG_ S_STD_0x136_S32_1 : 0|32@1- (1,0) [0|0] "" Vector__XXX
 SG_ S_STD_0x136_S16_1 : 32|16@1- (1,0) [0|0] "" Vector__XXX

BO_ 309 F_STD_0x135: 8 REF_ECU
 SG_ S_STD_0x135_S8_2 : 56|8@1- (1,0) [0|0] "" Vector__XXX
 SG_ S_STD_0x135_S8_1 : 48|8@1- (1,0) [0|0] "" Vector__XXX
 SG_ S_STD_0x135_S32_1 : 0|32@1- (1,0) [0|0] "" Vector__XXX
 SG_ S_STD_0x135_S16_1 : 32|16@1- (1,0) [0|0] "" Vector__XXX

BO_ 308 F_STD_0x134: 8 REF_ECU
 SG_ S_STD_0x134_S8_2 : 56|8@1- (1,0) [0|0] "" Vector__XXX
 SG_ S_STD_0x134_S8_1 : 48|8@1- (1,0) [0|0] "" Vector__XXX
 SG_ S_STD_0x134_S32_1 : 0|32@1- (1,0) [0|0] "" Vector__XXX
 SG_ S_STD_0x134_S16_1 : 32|16@1- (1,0) [0|0] "" Vector__XXX

BO_ 307 F_STD_0x133: 8 REF_ECU
 SG_ S_STD_0x133_S8_2 : 56|8@1- (1,0) [0|0] "" Vector__XXX
 SG_ S_STD_0x133_S8_1 : 48|8@1- (1,0) [0|0] "" Vector__XXX
 SG_ S_STD_0x133_S32_1 : 0|32@1- (1,0) [0|0] "" Vector__XXX
 SG_ S_STD_0x133_S16_1 : 32|16@1- (1,0) [0|0] "" Vector__XXX

BO_ 306 F_STD_0x132: 8 REF_ECU
 SG_ S_STD_0x132_S8_2 : 56|8@1- (1,0) [0|0] "" Vector__XXX
 SG_ S_STD_0x132_S8_1 : 48|8@1- (1,0) [0|0] "" Vector__XXX
 SG_ S_STD_0x132_S32_1 : 0|32@1- (1,0) [0|0] "" Vector__XXX
 SG_ S_STD_0x132_S16_1 : 32|16@1- (1,0) [0|0] "" Vector__XXX

BO_ 305 F_STD_0x131: 8 REF_ECU
 SG_ S_STD_0x131_S8_2 : 56|8@1- (1,0) [0|0] "" Vector__XXX
 SG_ S_STD_0x131_S8_1 : 48|8@1- (1,0) [0|0] "" Vector__XXX
 SG_ S_STD_0x131_S32_1 : 0|32@1- (1,0) [0|0] "" Vector__XXX
 SG_ S_STD_0x131_S16_1 : 32|16@1- (1,0) [0|0] "" Vector__XXX

BO_ 304 F_STD_0x130: 8 REF_ECU
 SG_ S_STD_0x130_S8_2 : 56|8@1- (1,0) [0|0] "" Vector__XXX
 SG_ S_STD_0x130_S8_1 : 48|8@1- (1,0) [0|0] "" Vector__XXX
 SG_ S_STD_0x130_S32_1 : 0|32@1- (1,0) [0|0] "" Vector__XXX
 SG_ S_STD_0x130_S16_1 : 32|16@1- (1,0) [0|0] "" Vector__XXX

BO_ 303 F_STD_0x12F: 8 REF_ECU
 SG_ S_STD_0x12F_S8_2 : 56|8@1- (1,0) [0|0] "" Vector__XXX
 SG_ S_STD_0x12F_S8_1 : 48|8@1- (1,0) [0|0] "" Vector__XXX
 SG_ S_STD_0x12F_S32_1 : 0|32@1- (1,0) [0|0] "" Vector__XXX
 SG_ S_STD_0x12F_S16_1 : 32|16@1- (1,0) [0|0] "" Vector__XXX

BO_ 302 F_STD_0x12E: 8 REF_ECU
 SG_ S_STD_0x12E_S8_2 : 56|8@1- (1,0) [0|0] "" Vector__XXX
 SG_ S_STD_0x12E_S8_1 : 48|8@1- (1,0) [0|0] "" Vector__XXX
 SG_ S_STD_0x12E_S32_1 : 0|32@1- (1,0) [0|0] "" Vector__XXX
 SG_ S_STD_0x12E_S16_1 : 32|16@1- (1,0) [0|0] "" Vector__XXX

BO_ 301 F_STD_0x12D: 8 REF_ECU
 SG_ S_STD_0x12D_S8_2 : 56|8@1- (1,0) [0|0] "" Vector__XXX
 SG_ S_STD_0x12D_S8_1 : 48|8@1- (1,0) [0|0] "" Vector__XXX
 SG_ S_STD_0x12D_S32_1 : 0|32@1- (1,0) [0|0] "" Vector__XXX
 SG_ S_STD_0x12D_S16_1 : 32|16@1- (1,0) [0|0] "" Vector__XXX

BO_ 300 F_STD_0x12C: 8 REF_ECU
 SG_ S_STD_0x12C_S8_2 : 56|8@1- (1,0) [0|0] "" Vector__XXX
 SG_ S_STD_0x12C_S8_1 : 48|8@1- (1,0) [0|0] "" Vector__XXX
 SG_ S_STD_0x12C_S32_1 : 0|32@1- (1,0) [0|0] "" Vector__XXX
 SG_ S_STD_0x12C_S16_1 : 32|16@1- (1,0) [0|0] "" Vector__XXX

BO_ 299 F_STD_0x12B: 8 REF_ECU
 SG_ S_STD_0x12B_S8_2 : 56|8@1- (1,0) [0|0] "" Vector__XXX
 SG_ S_STD_0x12B_S8_1 : 48|8@1- (1,0) [0|0] "" Vector__XXX
 SG_ S_STD_0x12B_S32_1 : 0|32@1- (1,0) [0|0] "" Vector__XXX
 SG_ S_STD_0x12B_S16_1 : 32|16@1- (1,0) [0|0] "" Vector__XXX

BO_ 298 F_STD_0x12A: 8 REF_ECU
 SG_ S_STD_0x12A_S8_2 : 56|8@1- (1,0) [0|0] "" Vector__XXX
 SG_ S_STD_0x12A_S8_1 : 48|8@1- (1,0) [0|0] "" Vector__XXX
 SG_ S_STD_0x12A_S32_1 : 0|32@1- (1,0) [0|0] "" Vector__XXX
 SG_ S_STD_0x12A_S16_1 : 32|16@1- (1,0) [0|0] "" Vector__XXX

BO_ 297 F_STD_0x129: 8 REF_ECU
 SG_ S_STD_0x129_S8_2 : 56|8@1- (1,0) [0|0] "" Vector__XXX
 SG_ S_STD_0x129_S8_1 : 48|8@1- (1,0) [0|0] "" Vector__XXX
 SG_ S_STD_0x129_S32_1 : 0|32@1- (1,0) [0|0] "" Vector__XXX
 SG_ S_STD_0x129_S16_1 : 32|16@1- (1,0) [0|0] "" Vector__XXX

BO_ 296 F_STD_0x128: 8 REF_ECU
 SG_ S_STD_0x128_S8_2 : 56|8@1- (1,0) [0|0] "" Vector__XXX
 SG_ S_STD_0x128_S8_1 : 48|8@1- (1,0) [0|0] "" Vector__XXX
 SG_ S_STD_0x128_S32_1 : 0|32@1- (1,0) [0|0] "" Vector__XXX
 SG_ S_STD_0x128_S16_1 : 32|16@1- (1,0) [0|0] "" Vector__XXX

BO_ 295 F_STD_0x127: 8 REF_ECU
 SG_ S_STD_0x127_S8_2 : 56|8@1- (1,0) [0|0] "" Vector__XXX
 SG_ S_STD_0x127_S8_1 : 48|8@1- (1,0) [0|0] "" Vector__XXX
 SG_ S_STD_0x127_S32_1 : 0|32@1- (1,0) [0|0] "" Vector__XXX
 SG_ S_STD_0x127_S16_1 : 32|16@1- (1,0) [0|0] "" Vector__XXX

BO_ 294 F_STD_0x126: 8 REF_ECU
 SG_ S_STD_0x126_S8_2 : 56|8@1- (1,0) [0|0] "" Vector__XXX
 SG_ S_STD_0x126_S8_1 : 48|8@1- (1,0) [0|0] "" Vector__XXX
 SG_ S_STD_0x126_S32_1 : 0|32@1- (1,0) [0|0] "" Vector__XXX
 SG_ S_STD_0x126_S16_1 : 32|16@1- (1,0) [0|0] "" Vector__XXX

BO_ 293 F_STD_0x125: 8 REF_ECU
 SG_ S_STD_0x125_S8_2 : 56|8@1- (1,0) [0|0] "" Vector__XXX
 SG_ S_STD_0x125_S8_1 : 48|8@1- (1,0) [0|0] "" Vector__XXX
 SG_ S_STD_0x125_S32_1 : 0|32@1- (1,0) [0|0] "" Vector__XXX
 SG_ S_STD_0x125_S16_1 : 32|16@1- (1,0) [0|0] "" Vector__XXX

BO_ 292 F_STD_0x124: 8 REF_ECU
 SG_ S_STD_0x124_S8_2 : 56|8@1- (1,0) [0|0] "" Vector__XXX
 SG_ S_STD_0x124_S8_1 : 48|8@1- (1,0) [0|0] "" Vector__XXX
 SG_ S_STD_0x124_S32_1 : 0|32@1- (1,0) [0|0] "" Vector__XXX
 SG_ S_STD_0x124_S16_1 : 32|16@1- (1,0) [0|0] "" Vector__XXX

BO_ 291 F_STD_0x123: 8 REF_ECU
 SG_ S_STD_0x123_S8_2 : 56|8@1- (1,0) [0|0] "" Vector__XXX
 SG_ S_STD_0x123_S8_1 : 48|8@1- (1,0) [0|0] "" Vector__XXX
 SG_ S_STD_0x123_S32_1 : 0|32@1- (1,0) [0|0] "" Vector__XXX
 SG_ S_STD_0x123_S16_1 : 32|16@1- (1,0) [0|0] "" Vector__XXX

BO_ 290 F_STD_0x122: 8 REF_ECU
 SG_ S_STD_0x122_S8_2 : 56|8@1- (1,0) [0|0] "" Vector__XXX
 SG_ S_STD_0x122_S8_1 : 48|8@1- (1,0) [0|0] "" Vector__XXX
 SG_ S_STD_0x122_S32_1 : 0|32@1- (1,0) [0|0] "" Vector__XXX
 SG_ S_STD_0x122_S16_1 : 32|16@1- (1,0) [0|0] "" Vector__XXX

BO_ 289 F_STD_0x121: 8 REF_ECU
 SG_ S_STD_0x121_S8_2 : 56|8@1- (1,0) [0|0] "" Vector__XXX
 SG_ S_STD_0x121_S8_1 : 48|8@1- (1,0) [0|0] "" Vector__XXX
 SG_ S_STD_0x121_S32_1 : 0|32@1- (1,0) [0|0] "" Vector__XXX
 SG_ S_STD_0x121_S16_1 : 32|16@1- (1,0) [0|0] "" Vector__XXX

BO_ 288 F_STD_0x120: 8 REF_ECU
 SG_ S_STD_0x120_S8_2 : 56|8@1- (1,0) [0|0] "" Vector__XXX
 SG_ S_STD_0x120_S8_1 : 48|8@1- (1,0) [0|0] "" Vector__XXX
 SG_ S_STD_0x120_S32_1 : 0|32@1- (1,0) [0|0] "" Vector__XXX
 SG_ S_STD_0x120_S16_1 : 32|16@1- (1,0) [0|0] "" Vector__XXX

BO_ 287 F_STD_0x11F: 8 REF_ECU
 SG_ S_STD_0x11F_S8_2 : 56|8@1- (1,0) [0|0] "" Vector__XXX
 SG_ S_STD_0x11F_S8_1 : 48|8@1- (1,0) [0|0] "" Vector__XXX
 SG_ S_STD_0x11F_S32_1 : 0|32@1- (1,0) [0|0] "" Vector__XXX
 SG_ S_STD_0x11F_S16_1 : 32|16@1- (1,0) [0|0] "" Vector__XXX

BO_ 286 F_STD_0x11E: 8 REF_ECU
 SG_ S_STD_0x11E_S8_2 : 56|8@1- (1,0) [0|0] "" Vector__XXX
 SG_ S_STD_0x11E_S8_1 : 48|8@1- (1,0) [0|0] "" Vector__XXX
 SG_ S_STD_0x11E_S32_1 : 0|32@1- (1,0) [0|0] "" Vector__XXX
 SG_ S_STD_0x11E_S16_1 : 32|16@1- (1,0) [0|0] "" Vector__XXX

BO_ 285 F_STD_0x11D: 8 REF_ECU
 SG_ S_STD_0x11D_S8_2 : 56|8@1- (1,0) [0|0] "" Vector__XXX
 SG_ S_STD_0x11D_S8_1 : 48|8@1- (1,0) [0|0] "" Vector__XXX
 SG_ S_STD_0x11D_S32_1 : 0|32@1- (1,0) [0|0] "" Vector__XXX
 SG_ S_STD_0x11D_S16_1 : 32|16@1- (1,0) [0|0] "" Vector__XXX

BO_ 284 F_STD_0x11C: 8 REF_ECU
 SG_ S_STD_0x11C_S8_2 : 56|8@1- (1,0) [0|0] "" Vector__XXX
 SG_ S_STD_0x11C_S8_1 : 48|8@1- (1,0) [0|0] "" Vector__XXX
 SG_ S_STD_0x11C_S32_1 : 0|32@1- (1,0) [0|0] "" Vector__XXX
 SG_ S_STD_0x11C_S16_1 : 32|16@1- (1,0) [0|0] "" Vector__XXX

BO_ 283 F_STD_0x11B: 8 REF_ECU
 SG_ S_STD_0x11B_S8_2 : 56|8@1- (1,0) [0|0] "" Vector__XXX
 SG_ S_STD_0x11B_S8_1 : 48|8@1- (1,0) [0|0] "" Vector__XXX
 SG_ S_STD_0x11B_S32_1 : 0|32@1- (1,0) [0|0] "" Vector__XXX
 SG_ S_STD_0x11B_S16_1 : 32|16@1- (1,0) [0|0] "" Vector__XXX

BO_ 282 F_STD_0x11A: 8 REF_ECU
 SG_ S_STD_0x11A_S8_2 : 56|8@1- (1,0) [0|0] "" Vector__XXX
 SG_ S_STD_0x11A_S8_1 : 48|8@1- (1,0) [0|0] "" Vector__XXX
 SG_ S_STD_0x11A_S32_1 : 0|32@1- (1,0) [0|0] "" Vector__XXX
 SG_ S_STD_0x11A_S16_1 : 32|16@1- (1,0) [0|0] "" Vector__XXX

BO_ 281 F_STD_0x119: 8 REF_ECU
 SG_ S_STD_0x119_S8_2 : 56|8@1- (1,0) [0|0] "" Vector__XXX
 SG_ S_STD_0x119_S8_1 : 48|8@1- (1,0) [0|0] "" Vector__XXX
 SG_ S_STD_0x119_S32_1 : 0|32@1- (1,0) [0|0] "" Vector__XXX
 SG_ S_STD_0x119_S16_1 : 32|16@1- (1,0) [0|0] "" Vector__XXX

BO_ 280 F_STD_0x118: 8 REF_ECU
 SG_ S_STD_0x118_S8_2 : 56|8@1- (1,0) [0|0] "" Vector__XXX
 SG_ S_STD_0x118_S8_1 : 48|8@1- (1,0) [0|0] "" Vector__XXX
 SG_ S_STD_0x118_S32_1 : 0|32@1- (1,0) [0|0] "" Vector__XXX
 SG_ S_STD_0x118_S16_1 : 32|16@1- (1,0) [0|0] "" Vector__XXX

BO_ 279 F_STD_0x117: 8 REF_ECU
 SG_ S_STD_0x117_S8_2 : 56|8@1- (1,0) [0|0] "" Vector__XXX
 SG_ S_STD_0x117_S8_1 : 48|8@1- (1,0) [0|0] "" Vector__XXX
 SG_ S_STD_0x117_S32_1 : 0|32@1- (1,0) [0|0] "" Vector__XXX
 SG_ S_STD_0x117_S16_1 : 32|16@1- (1,0) [0|0] "" Vector__XXX

BO_ 278 F_STD_0x116: 8 REF_ECU
 SG_ S_STD_0x116_S8_2 : 56|8@1- (1,0) [0|0] "" Vector__XXX
 SG_ S_STD_0x116_S8_1 : 48|8@1- (1,0) [0|0] "" Vector__XXX
 SG_ S_STD_0x116_S32_1 : 0|32@1- (1,0) [0|0] "" Vector__XXX
 SG_ S_STD_0x116_S16_1 : 32|16@1- (1,0) [0|0] "" Vector__XXX

BO_ 277 F_STD_0x115: 8 REF_ECU
 SG_ S_STD_0x115_S8_2 : 56|8@1- (1,0) [0|0] "" Vector__XXX
 SG_ S_STD_0x115_S8_1 : 48|8@1- (1,0) [0|0] "" Vector__XXX
 SG_ S_STD_0x115_S32_1 : 0|32@1- (1,0) [0|0] "" Vector__XXX
 SG_ S_STD_0x115_S16_1 : 32|16@1- (1,0) [0|0] "" Vector__XXX

BO_ 276 F_STD_0x114: 8 REF_ECU
 SG_ S_STD_0x114_S8_2 : 56|8@1- (1,0) [0|0] "" Vector__XXX
 SG_ S_STD_0x114_S8_1 : 48|8@1- (1,0) [0|0] "" Vector__XXX
 SG_ S_STD_0x114_S32_1 : 0|32@1- (1,0) [0|0] "" Vector__XXX
 SG_ S_STD_0x114_S16_1 : 32|16@1- (1,0) [0|0] "" Vector__XXX

BO_ 275 F_STD_0x113: 8 REF_ECU
 SG_ S_STD_0x113_S8_2 : 56|8@1- (1,0) [0|0] "" Vector__XXX
 SG_ S_STD_0x113_S8_1 : 48|8@1- (1,0) [0|0] "" Vector__XXX
 SG_ S_STD_0x113_S32_1 : 0|32@1- (1,0) [0|0] "" Vector__XXX
 SG_ S_STD_0x113_S16_1 : 32|16@1- (1,0) [0|0] "" Vector__XXX

BO_ 274 F_STD_0x112: 8 REF_ECU
 SG_ S_STD_0x112_S8_2 : 56|8@1- (1,0) [0|0] "" Vector__XXX
 SG_ S_STD_0x112_S8_1 : 48|8@1- (1,0) [0|0] "" Vector__XXX
 SG_ S_STD_0x112_S32_1 : 0|32@1- (1,0) [0|0] "" Vector__XXX
 SG_ S_STD_0x112_S16_1 : 32|16@1- (1,0) [0|0] "" Vector__XXX

BO_ 273 F_STD_0x111: 8 REF_ECU
 SG_ S_STD_0x111_S8_2 : 56|8@1- (1,0) [0|0] "" Vector__XXX
 SG_ S_STD_0x111_S8_1 : 48|8@1- (1,0) [0|0] "" Vector__XXX
 SG_ S_STD_0x111_S32_1 : 0|32@1- (1,0) [0|0] "" Vector__XXX
 SG_ S_STD_0x111_S16_1 : 32|16@1- (1,0) [0|0] "" Vector__XXX

BO_ 272 F_STD_0x110: 8 REF_ECU
 SG_ S_STD_0x110_S8_2 : 56|8@1- (1,0) [0|0] "" Vector__XXX
 SG_ S_STD_0x110_S8_1 : 48|8@1- (1,0) [0|0] "" Vector__XXX
 SG_ S_STD_0x110_S32_1 : 0|32@1- (1,0) [0|0] "" Vector__XXX
 SG_ S_STD_0x110_S16_1 : 32|16@1- (1,0) [0|0] "" Vector__XXX

BO_ 271 F_STD_0x10F: 8 REF_ECU
 SG_ S_STD_0x10F_S8_2 : 56|8@1- (1,0) [0|0] "" Vector__XXX
 SG_ S_STD_0x10F_S8_1 : 48|8@1- (1,0) [0|0] "" Vector__XXX
 SG_ S_STD_0x10F_S32_1 : 0|32@1- (1,0) [0|0] "" Vector__XXX
 SG_ S_STD_0x10F_S16_1 : 32|16@1- (1,0) [0|0] "" Vector__XXX

BO_ 270 F_STD_0x10E: 8 REF_ECU
 SG_ S_STD_0x10E_S8_2 : 56|8@1- (1,0) [0|0] "" Vector__XXX
 SG_ S_STD_0x10E_S8_1 : 48|8@1- (1,0) [0|0] "" Vector__XXX
 SG_ S_STD_0x10E_S32_1 : 0|32@1- (1,0) [0|0] "" Vector__XXX
 SG_ S_STD_0x10E_S16_1 : 32|16@1- (1,0) [0|0] "" Vector__XXX

BO_ 269 F_STD_0x10D: 8 REF_ECU
 SG_ S_STD_0x10D_S8_2 : 56|8@1- (1,0) [0|0] "" Vector__XXX
 SG_ S_STD_0x10D_S8_1 : 48|8@1- (1,0) [0|0] "" Vector__XXX
 SG_ S_STD_0x10D_S32_1 : 0|32@1- (1,0) [0|0] "" Vector__XXX
 SG_ S_STD_0x10D_S16_1 : 32|16@1- (1,0) [0|0] "" Vector__XXX

BO_ 268 F_STD_0x10C: 8 REF_ECU
 SG_ S_STD_0x10C_S8_2 : 56|8@1- (1,0) [0|0] "" Vector__XXX
 SG_ S_STD_0x10C_S8_1 : 48|8@1- (1,0) [0|0] "" Vector__XXX
 SG_ S_STD_0x10C_S32_1 : 0|32@1- (1,0) [0|0] "" Vector__XXX
 SG_ S_STD_0x10C_S16_1 : 32|16@1- (1,0) [0|0] "" Vector__XXX

BO_ 267 F_STD_0x10B: 8 REF_ECU
 SG_ S_STD_0x10B_S8_2 : 56|8@1- (1,0) [0|0] "" Vector__XXX
 SG_ S_STD_0x10B_S8_1 : 48|8@1- (1,0) [0|0] "" Vector__XXX
 SG_ S_STD_0x10B_S32_1 : 0|32@1- (1,0) [0|0] "" Vector__XXX
 SG_ S_STD_0x10B_S16_1 : 32|16@1- (1,0) [0|0] "" Vector__XXX

BO_ 266 F_STD_0x10A: 8 REF_ECU
 SG_ S_STD_0x10A_S8_2 : 56|8@1- (1,0) [0|0] "" Vector__XXX
 SG_ S_STD_0x10A_S8_1 : 48|8@1- (1,0) [0|0] "" Vector__XXX
 SG_ S_STD_0x10A_S32_1 : 0|32@1- (1,0) [0|0] "" Vector__XXX
 SG_ S_STD_0x10A_S16_1 : 32|16@1- (1,0) [0|0] "" Vector__XXX

BO_ 265 F_STD_0x109: 8 REF_ECU
 SG_ S_STD_0x109_S8_2 : 56|8@1- (1,0) [0|0] "" Vector__XXX
 SG_ S_STD_0x109_S8_1 : 48|8@1- (1,0) [0|0] "" Vector__XXX
 SG_ S_STD_0x109_S32_1 : 0|32@1- (1,0) [0|0] "" Vector__XXX
 SG_ S_STD_0x109_S16_1 : 32|16@1- (1,0) [0|0] "" Vector__XXX

BO_ 264 F_STD_0x108: 8 REF_ECU
 SG_ S_STD_0x108_S8_2 : 56|8@1- (1,0) [0|0] "" Vector__XXX
 SG_ S_STD_0x108_S8_1 : 48|8@1- (1,0) [0|0] "" Vector__XXX
 SG_ S_STD_0x108_S32_1 : 0|32@1- (1,0) [0|0] "" Vector__XXX
 SG_ S_STD_0x108_S16_1 : 32|16@1- (1,0) [0|0] "" Vector__XXX

BO_ 263 F_STD_0x107: 8 REF_ECU
 SG_ S_STD_0x107_S8_2 : 56|8@1- (1,0) [0|0] "" Vector__XXX
 SG_ S_STD_0x107_S8_1 : 48|8@1- (1,0) [0|0] "" Vector__XXX
 SG_ S_STD_0x107_S32_1 : 0|32@1- (1,0) [0|0] "" Vector__XXX
 SG_ S_STD_0x107_S16_1 : 32|16@1- (1,0) [0|0] "" Vector__XXX

BO_ 262 F_STD_0x106: 8 REF_ECU
 SG_ S_STD_0x106_S8_2 : 56|8@1- (1,0) [0|0] "" Vector__XXX
 SG_ S_STD_0x106_S8_1 : 48|8@1- (1,0) [0|0] "" Vector__XXX
 SG_ S_STD_0x106_S32_1 : 0|32@1- (1,0) [0|0] "" Vector__XXX
 SG_ S_STD_0x106_S16_1 : 32|16@1- (1,0) [0|0] "" Vector__XXX

BO_ 261 F_STD_0x105: 8 REF_ECU
 SG_ S_STD_0x105_S8_2 : 56|8@1- (1,0) [0|0] "" Vector__XXX
 SG_ S_STD_0x105_S8_1 : 48|8@1- (1,0) [0|0] "" Vector__XXX
 SG_ S_STD_0x105_S32_1 : 0|32@1- (1,0) [0|0] "" Vector__XXX
 SG_ S_STD_0x105_S16_1 : 32|16@1- (1,0) [0|0] "" Vector__XXX

BO_ 260 F_STD_0x104: 8 REF_ECU
 SG_ S_STD_0x104_S8_2 : 56|8@1- (1,0) [0|0] "" Vector__XXX
 SG_ S_STD_0x104_S8_1 : 48|8@1- (1,0) [0|0] "" Vector__XXX
 SG_ S_STD_0x104_S32_1 : 0|32@1- (1,0) [0|0] "" Vector__XXX
 SG_ S_STD_0x104_S16_1 : 32|16@1- (1,0) [0|0] "" Vector__XXX

BO_ 259 F_STD_0x103: 8 REF_ECU
 SG_ S_STD_0x103_S8_2 : 56|8@1- (1,0) [0|0] "" Vector__XXX
 SG_ S_STD_0x103_S8_1 : 48|8@1- (1,0) [0|0] "" Vector__XXX
 SG_ S_STD_0x103_S32_1 : 0|32@1- (1,0) [0|0] "" Vector__XXX
 SG_ S_STD_0x103_S16_1 : 32|16@1- (1,0) [0|0] "" Vector__XXX

BO_ 258 F_STD_0x102: 8 REF_ECU
 SG_ S_STD_0x102_S8_2 : 56|8@1- (1,0) [0|0] "" Vector__XXX
 SG_ S_STD_0x102_S8_1 : 48|8@1- (1,0) [0|0] "" Vector__XXX
 SG_ S_STD_0x102_S32_1 : 0|32@1- (1,0) [0|0] "" Vector__XXX
 SG_ S_STD_0x102_S16_1 : 32|16@1- (1,0) [0|0] "" Vector__XXX

BO_ 257 F_STD_0x101: 8 REF_ECU
 SG_ S_STD_0x101_S8_2 : 56|8@1- (1,0) [0|0] "" Vector__XXX
 SG_ S_STD_0x101_S8_1 : 48|8@1- (1,0) [0|0] "" Vector__XXX
 SG_ S_STD_0x101_S32_1 : 0|32@1- (1,0) [0|0] "" Vector__XXX
 SG_ S_STD_0x101_S16_1 : 32|16@1- (1,0) [0|0] "" Vector__XXX

BO_ 256 F_STD_0x100: 8 REF_ECU
 SG_ S_STD_0x100_S8_2 : 56|8@1- (1,0) [0|0] "" Vector__XXX
 SG_ S_STD_0x100_S8_1 : 48|8@1- (1,0) [0|0] "" Vector__XXX
 SG_ S_STD_0x100_S32_1 : 0|32@1- (1,0) [0|0] "" Vector__XXX
 SG_ S_STD_0x100_S16_1 : 32|16@1- (1,0) [0|0] "" Vector__XXX

BA_DEF_  "BusType" STRING ;
BA_DEF_DEF_  "BusType" "CAN";
